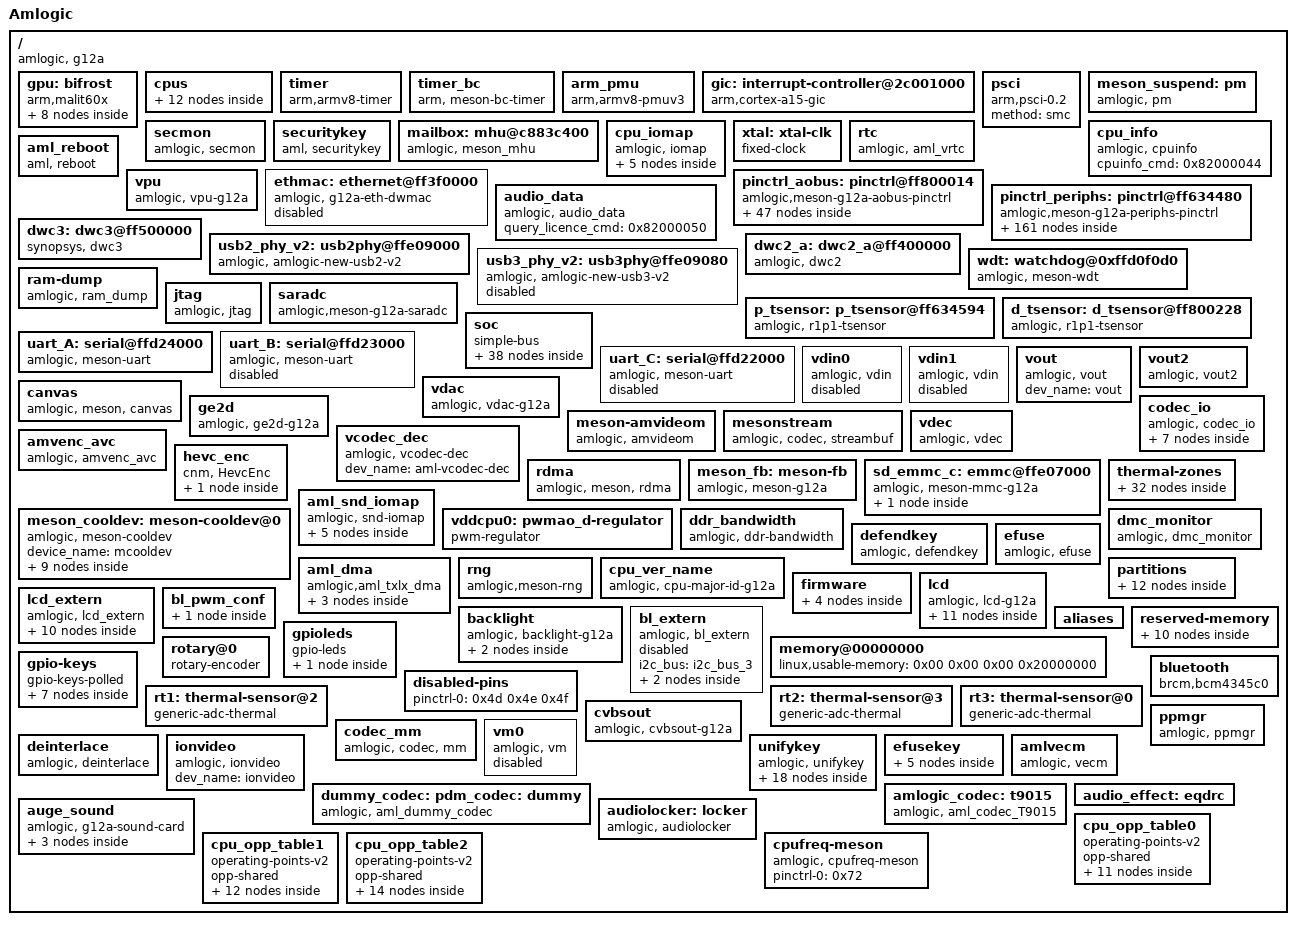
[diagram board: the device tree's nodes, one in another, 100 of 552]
/dts-v1/;

/ {
	model = "Amlogic";
	amlogic-dt-id = "g12a_evt_1g";
	compatible = "amlogic, g12a";
	interrupt-parent = <0x01>;
	#address-cells = <0x02>;
	#size-cells = <0x02>;

	gpu: bifrost {
		compatible = "arm,malit60x", "arm,malit6xx", "arm,mali-midgard";
		#cooling-cells = <0x02>;
		reg = <0x00 0xffe40000 0x00 0x4000>, <0x00 0xffd01000 0x00 0x1000>, <0x00 0xff800000 0x00 0x1000>, <0x00 0xff63c000 0x00 0x1000>, <0x00 0xffd01000 0x00 0x1000>;
		interrupt-parent = <0x01>;
		interrupts = <0x00 0xa0 0x04>, <0x00 0xa1 0x04>, <0x00 0xa2 0x04>;
		interrupt-names = "GPU", "MMU", "JOB";
		num_of_pp = <0x02>;
		sc_mpp = <0x01>;
		clocks = <0x02 0x83 0x02 0x07>;
		clock-names = "gpu_mux", "gp0_pll";
		tbl = <0x03 0x04 0x05 0x06 0x07 0x07>;

		dvfs125_cfg: clk125_cfg {
			clk_freq = <0x7735940>;
			clk_parent = "fclk_div4";
			clkp_freq = <0x1dcd6500>;
			clk_reg = <0xa03>;
			voltage = <0x47e>;
			keep_count = <0x05>;
			threshold = <0x1e 0x78>;
		};

		dvfs250_cfg: dvfs250_cfg {
			clk_freq = <0xee6b280>;
			clk_parent = "fclk_div4";
			clkp_freq = <0x1dcd6500>;
			clk_reg = <0xa01>;
			voltage = <0x47e>;
			keep_count = <0x05>;
			threshold = <0x50 0xaa>;
		};

		dvfs285_cfg: dvfs285_cfg {
			clk_freq = <0x1107a76d>;
			clk_parent = "fclk_div7";
			clkp_freq = <0x1107a76d>;
			clk_reg = <0xe00>;
			voltage = <0x47e>;
			keep_count = <0x05>;
			threshold = <0x64 0xbe>;
			phandle = <0x03>;
		};

		dvfs400_cfg: dvfs400_cfg {
			clk_freq = <0x17d78400>;
			clk_parent = "fclk_div5";
			clkp_freq = <0x17d78400>;
			clk_reg = <0xc00>;
			voltage = <0x47e>;
			keep_count = <0x05>;
			threshold = <0x98 0xcf>;
			phandle = <0x04>;
		};

		dvfs500_cfg: dvfs500_cfg {
			clk_freq = <0x1dcd6500>;
			clk_parent = "fclk_div4";
			clkp_freq = <0x1dcd6500>;
			clk_reg = <0xa00>;
			voltage = <0x47e>;
			keep_count = <0x05>;
			threshold = <0xb4 0xdc>;
			phandle = <0x05>;
		};

		dvfs666_cfg: dvfs666_cfg {
			clk_freq = <0x27bc86aa>;
			clk_parent = "fclk_div3";
			clkp_freq = <0x27bc86aa>;
			clk_reg = <0x800>;
			voltage = <0x47e>;
			keep_count = <0x05>;
			threshold = <0xd2 0xec>;
			phandle = <0x06>;
		};

		dvfs800_cfg: dvfs800_cfg {
			clk_freq = <0x2faf0800>;
			clk_parent = "fclk_div2p5";
			clkp_freq = <0x2faf0800>;
			clk_reg = <0x600>;
			voltage = <0x47e>;
			keep_count = <0x05>;
			threshold = <0xe6 0xff>;
		};

		dvfs850_cfg: dvfs850_cfg {
			clk_freq = <0x326cef80>;
			clk_parent = "gp0_pll";
			clkp_freq = <0x326cef80>;
			clk_reg = <0x200>;
			voltage = <0x47e>;
			keep_count = <0x05>;
			threshold = <0xe6 0xff>;
			phandle = <0x07>;
		};
	};

	cpus: cpus {
		#address-cells = <0x02>;
		#size-cells = <0x00>;

		cpu-map {

			cluster0: cluster0 {

				core0 {
					cpu = <0x08>;
				};

				core1 {
					cpu = <0x09>;
				};

				core2 {
					cpu = <0x0a>;
				};

				core3 {
					cpu = <0x0b>;
				};
			};
		};

		CPU0: cpu@0 {
			device_type = "cpu";
			compatible = "arm,cortex-a53", "arm,armv8";
			reg = <0x00 0x00>;
			enable-method = "psci";
			cpu-idle-states = <0x0c>;
			clocks = <0x02 0x17>, < 0x02 0x16>, < 0x02 0x00>;
			clock-names = "core_clk", "low_freq_clk_parent", "high_freq_clk_parent";
			operating-points-v2 = <0x0d>, < 0x0e>, < 0x0f>;
			cpu-supply = <0x10>;
			voltage-tolerance = <0x00>;
			clock-latency = <0xc350>;
			diff_tables_supply;
			hispeed_cpufreq_max = <0x834>;
			medspeed_cpufreq_max = <0x774>;
			lospeed_cpufreq_max = <0x708>;
			phandle = <0x08>;
		};

		CPU1: cpu@1 {
			device_type = "cpu";
			compatible = "arm,cortex-a53", "arm,armv8";
			reg = <0x00 0x01>;
			enable-method = "psci";
			cpu-idle-states = <0x0c>;
			clocks = <0x02 0x17>, < 0x02 0x16>, < 0x02 0x00>;
			clock-names = "core_clk", "low_freq_clk_parent", "high_freq_clk_parent";
			operating-points-v2 = <0x0d>, < 0x0e>, < 0x0f>;
			cpu-supply = <0x10>;
			voltage-tolerance = <0x00>;
			clock-latency = <0xc350>;
			diff_tables_supply;
			hispeed_cpufreq_max = <0x834>;
			medspeed_cpufreq_max = <0x774>;
			lospeed_cpufreq_max = <0x708>;
			phandle = <0x09>;
		};

		CPU2: cpu@2 {
			device_type = "cpu";
			compatible = "arm,cortex-a53", "arm,armv8";
			reg = <0x00 0x02>;
			enable-method = "psci";
			cpu-idle-states = <0x0c>;
			clocks = <0x02 0x17>, < 0x02 0x16>, < 0x02 0x00>;
			clock-names = "core_clk", "low_freq_clk_parent", "high_freq_clk_parent";
			operating-points-v2 = <0x0d>, < 0x0e>, < 0x0f>;
			cpu-supply = <0x10>;
			voltage-tolerance = <0x00>;
			clock-latency = <0xc350>;
			diff_tables_supply;
			hispeed_cpufreq_max = <0x834>;
			medspeed_cpufreq_max = <0x774>;
			lospeed_cpufreq_max = <0x708>;
			phandle = <0x0a>;
		};

		CPU3: cpu@3 {
			device_type = "cpu";
			compatible = "arm,cortex-a53", "arm,armv8";
			reg = <0x00 0x03>;
			enable-method = "psci";
			cpu-idle-states = <0x0c>;
			clocks = <0x02 0x17>, < 0x02 0x16>, < 0x02 0x00>;
			clock-names = "core_clk", "low_freq_clk_parent", "high_freq_clk_parent";
			operating-points-v2 = <0x0d>, < 0x0e>, < 0x0f>;
			cpu-supply = <0x10>;
			voltage-tolerance = <0x00>;
			clock-latency = <0xc350>;
			diff_tables_supply;
			hispeed_cpufreq_max = <0x834>;
			medspeed_cpufreq_max = <0x774>;
			lospeed_cpufreq_max = <0x708>;
			phandle = <0x0b>;
		};

		idle-states {
			entry-method = "arm,psci-0.2";

			CPU_SLEEP_0: cpu-sleep-0 {
				compatible = "arm,idle-state";
				arm,psci-suspend-param = <0x10000>;
				local-timer-stop;
				entry-latency-us = <0x1388>;
				exit-latency-us = <0x1388>;
				min-residency-us = <0x3a98>;
				phandle = <0x0c>;
			};
		};
	};

	timer {
		compatible = "arm,armv8-timer";
		interrupts = <0x01 0x0d 0xff08>, <0x01 0x0e 0xff08>, <0x01 0x0b 0xff08>, <0x01 0x0a 0xff08>;
	};

	timer_bc {
		compatible = "arm, meson-bc-timer";
		reg = <0x00 0xffd0f190 0x00 0x04 0x00 0xffd0f194 0x00 0x04>;
		timer_name = "Meson TimerF";
		clockevent-rating = <0x12c>;
		clockevent-shift = <0x14>;
		clockevent-features = <0x23>;
		interrupts = <0x00 0x3c 0x01>;
		bit_enable = <0x10>;
		bit_mode = <0x0c>;
		bit_resolution = <0x00>;
	};

	arm_pmu {
		compatible = "arm,armv8-pmuv3";
		interrupts = <0x00 0x89 0x04>;
		reg = <0x00 0xff634680 0x00 0x04>;
		cpumasks = <0x0f>;
		relax-timer-ns = <0x989680>;
		max-wait-cnt = <0x2710>;
	};

	gic: interrupt-controller@2c001000 {
		compatible = "arm,cortex-a15-gic", "arm,cortex-a9-gic";
		#interrupt-cells = <0x03>;
		#address-cells = <0x00>;
		interrupt-controller;
		reg = <0x00 0xffc01000 0x00 0x1000>, <0x00 0xffc02000 0x00 0x100>;
		interrupts = <0x01 0x09 0xf04>;
		phandle = <0x01>;
	};

	psci {
		compatible = "arm,psci-0.2";
		method = "smc";
	};

	meson_suspend: pm {
		compatible = "amlogic, pm";
		status = "okay";
		device_name = "aml_pm";
		reg = <0x00 0xff8000a8 0x00 0x04>, <0x00 0xff80023c 0x00 0x04>;
	};

	secmon {
		compatible = "amlogic, secmon";
		memory-region = <0x11>;
		in_base_func = <0x82000020>;
		out_base_func = <0x82000021>;
		reserve_mem_size = <0x300000>;
	};

	securitykey {
		compatible = "aml, securitykey";
		storage_query = <0x82000060>;
		storage_read = <0x82000061>;
		storage_write = <0x82000062>;
		storage_tell = <0x82000063>;
		storage_verify = <0x82000064>;
		storage_status = <0x82000065>;
		storage_list = <0x82000067>;
		storage_remove = <0x82000068>;
		storage_in_func = <0x82000023>;
		storage_out_func = <0x82000024>;
		storage_block_func = <0x82000025>;
		storage_size_func = <0x82000027>;
		storage_set_enctype = <0x8200006a>;
		storage_get_enctype = <0x8200006b>;
		storage_version = <0x8200006c>;
	};

	mailbox: mhu@c883c400 {
		compatible = "amlogic, meson_mhu";
		reg = <0x00 0xff63c400 0x00 0x4c>, <0x00 0xfffe7000 0x00 0x800>;
		interrupts = <0x00 0xd1 0x01>, <0x00 0xd2 0x01>;
		#mbox-cells = <0x01>;
		mbox-names = "cpu_to_scp_low", "cpu_to_scp_high";
		mboxes = <0x12 0x00 0x12 0x01>;
		phandle = <0x12>;
	};

	cpu_iomap {
		compatible = "amlogic, iomap";
		#address-cells = <0x02>;
		#size-cells = <0x02>;
		ranges;

		io_cbus_base {
			reg = <0x00 0xffd00000 0x00 0x26000>;
		};

		io_apb_base {
			reg = <0x00 0xffe01000 0x00 0x7f000>;
		};

		io_aobus_base {
			reg = <0x00 0xff800000 0x00 0xb000>;
		};

		io_vapb_base {
			reg = <0x00 0xff900000 0x00 0x50000>;
		};

		io_hiu_base {
			reg = <0x00 0xff63c000 0x00 0x2000>;
		};
	};

	xtal: xtal-clk {
		compatible = "fixed-clock";
		clock-frequency = <0x16e3600>;
		clock-output-names = "xtal";
		#clock-cells = <0x00>;
		phandle = <0x16>;
	};

	rtc {
		compatible = "amlogic, aml_vrtc";
		alarm_reg_addr = <0xff8000a8>;
		timer_e_addr = <0xffd0f188>;
		init_date = "2015/01/01";
		status = "okay";
	};

	cpu_info {
		compatible = "amlogic, cpuinfo";
		status = "okay";
		cpuinfo_cmd = <0x82000044>;
	};

	aml_reboot {
		compatible = "aml, reboot";
		sys_reset = <0x84000009>;
		sys_poweroff = <0x84000008>;
	};

	vpu {
		compatible = "amlogic, vpu-g12a";
		dev_name = "vpu";
		status = "okay";
		clocks = <0x02 0x95>, < 0x02 0x4c>, < 0x02 0x87>, < 0x02 0x8b>, < 0x02 0x8c>;
		clock-names = "vapb_clk", "vpu_intr_gate", "vpu_clk0", "vpu_clk1", "vpu_clk";
		clk_level = <0x07>;
	};

	ethmac: ethernet@ff3f0000 {
		compatible = "amlogic, g12a-eth-dwmac", "snps,dwmac";
		reg = <0x00 0xff3f0000 0x00 0x10000 0x00 0xff634540 0x00 0x08 0x00 0xff64c000 0x00 0xa0>;
		reg-names = "eth_base", "eth_cfg", "eth_pll";
		interrupts = <0x00 0x08 0x01>;
		interrupt-names = "macirq";
		status = "disabled";
		clocks = <0x02 0x38>;
		clock-names = "ethclk81";
		pll_val = <0x9c0040a 0x927e0000 0xac5f49e5>;
		analog_val = <0x20200000 0xc000 0x23>;
	};

	pinctrl_aobus: pinctrl@ff800014 {
		compatible = "amlogic,meson-g12a-aobus-pinctrl";
		#address-cells = <0x02>;
		#size-cells = <0x02>;
		ranges;

		gpio_ao: ao-bank@ff800014 {
			reg = <0x00 0xff800014 0x00 0x08>, <0x00 0xff800024 0x00 0x14>, <0x00 0xff80001c 0x00 0x08>;
			reg-names = "mux", "gpio", "drive-strength";
			gpio-controller;
			#gpio-cells = <0x02>;
			phandle = <0x4a>;
		};

		sd_to_ao_uart_clr_pins: sd_to_ao_uart_clr_pins {

			mux {
				groups = "GPIOAO_0", "GPIOAO_1";
				function = "gpio_aobus";
			};
		};

		sd_to_ao_uart_pins: sd_to_ao_uart_pins {

			mux {
				groups = "uart_ao_tx_a", "uart_ao_rx_a";
				function = "uart_ao_a";
				bias-pull-up;
				input-enable;
			};
		};

		ao_uart_pins: ao_uart {
			phandle = <0x1f>;

			mux {
				groups = "uart_ao_tx_a", "uart_ao_rx_a";
				function = "uart_ao_a";
			};
		};

		ao_b_uart_pins: ao_b_uart {
			phandle = <0x20>;

			mux {
				groups = "uart_ao_tx_b_2", "uart_ao_rx_b_3";
				function = "uart_ao_b";
			};
		};

		ao_i2c_master_pins1: ao_i2c_pins1 {

			mux {
				groups = "i2c_ao_sck", "i2c_ao_sda";
				function = "i2c_ao";
				drive-strength = <0x02>;
			};
		};

		ao_i2c_master_pins2: ao_i2c_pins2 {

			mux {
				groups = "i2c_ao_sck_e", "i2c_ao_sda_e";
				function = "i2c_ao";
				drive-strength = <0x02>;
			};
		};

		ao_i2c_slave_pins: ao_i2c_slave_pins {
			phandle = <0x1e>;

			mux {
				groups = "i2c_ao_slave_sck", "i2c_ao_slave_sda";
				function = "i2c_ao_slave";
			};
		};

		pwm_ao_a_pins: pwm_ao_a {

			mux {
				groups = "pwm_ao_a";
				function = "pwm_ao_a";
			};
		};

		pwm_ao_a_hiz_pins: pwm_ao_a_hiz {

			mux {
				groups = "pwm_ao_a_hiz";
				function = "pwm_ao_a";
			};
		};

		pwm_ao_b_pins: pwm_ao_b {

			mux {
				groups = "pwm_ao_b";
				function = "pwm_ao_b";
			};
		};

		pwm_ao_c_pins1: pwm_ao_c_pins1 {

			mux {
				groups = "pwm_ao_c_4";
				function = "pwm_ao_c";
			};
		};

		pwm_ao_c_pins2: pwm_ao_c_pins2 {

			mux {
				groups = "pwm_ao_c_6";
				function = "pwm_ao_c";
			};
		};

		pwm_ao_c_hiz_pins: pwm_ao_c_hiz {

			mux {
				groups = "pwm_ao_c_hiz_4";
				function = "pwm_ao_c";
			};
		};

		pwm_ao_d_pins1: pwm_ao_d_pins1 {

			mux {
				groups = "pwm_ao_d_5";
				function = "pwm_ao_d";
			};
		};

		pwm_ao_d_pins2: pwm_ao_d_pins2 {

			mux {
				groups = "pwm_ao_d_10";
				function = "pwm_ao_d";
			};
		};

		pwm_ao_d_pins3: pwm_ao_d_pins3 {
			phandle = <0x72>;

			mux {
				groups = "pwm_ao_d_e";
				function = "pwm_ao_d";
			};
		};

		aocec_a: ao_ceca {

			mux {
				groups = "cec_ao_a";
				function = "cec_ao";
			};
		};

		aocec_b: ao_cecb {

			mux {
				groups = "cec_ao_b";
				function = "cec_ao";
			};
		};

		jtag_apao_pins: jtag_apao_pin {
			phandle = <0x17>;

			mux {
				groups = "jtag_a_tdi", "jtag_a_tdo", "jtag_a_clk", "jtag_a_tms";
				function = "jtag_a";
			};
		};

		remote_pins: remote_pin {

			mux {
				groups = "remote_input_ao";
				function = "remote_input_ao";
			};
		};

		irblaster_pins: irblaster_pin {
			phandle = <0x21>;

			mux {
				groups = "remote_out_ao";
				function = "remote_out_ao";
			};
		};

		spdifout: spdifout {

			mux {
				groups = "spdif_out_ao";
				function = "spdif_out_ao";
			};
		};

		spdifout_a_mute: spdifout_a_mute {

			mux {
				groups = "GPIOAO_10";
				function = "gpio_aobus";
			};
		};
	};

	pinctrl_periphs: pinctrl@ff634480 {
		compatible = "amlogic,meson-g12a-periphs-pinctrl";
		#address-cells = <0x02>;
		#size-cells = <0x02>;
		ranges;

		gpio: banks@ff6346c0 {
			reg = <0x00 0xff6346c0 0x00 0x40>, <0x00 0xff6344e8 0x00 0x18>, <0x00 0xff634520 0x00 0x18>, <0x00 0xff634440 0x00 0x4c>, <0x00 0xff634740 0x00 0x1c>;
			reg-names = "mux", "pull", "pull-enable", "gpio", "drive-strength";
			gpio-controller;
			#gpio-cells = <0x02>;
			phandle = <0x15>;
		};

		emmc_clk_cmd_pins: emmc_clk_cmd_pins {
			phandle = <0x2b>;

			mux {
				groups = "emmc_clk", "emmc_cmd";
				function = "emmc";
				input-enable;
				bias-pull-up;
			};
		};

		emmc_conf_pull_up: emmc_conf_pull_up {
			phandle = <0x2c>;

			mux {
				groups = "emmc_nand_d7", "emmc_nand_d6", "emmc_nand_d5", "emmc_nand_d4", "emmc_nand_d3", "emmc_nand_d2", "emmc_nand_d1", "emmc_nand_d0", "emmc_clk", "emmc_cmd";
				function = "emmc";
				input-enable;
				bias-pull-up;
			};
		};

		emmc_conf_pull_done: emmc_conf_pull_done {
			phandle = <0x2d>;

			mux {
				groups = "emmc_nand_ds";
				function = "emmc";
				input-enable;
				bias-pull-down;
			};
		};

		sd_clk_cmd_pins: sd_clk_cmd_pins {

			mux {
				groups = "sdcard_cmd_c";
				function = "sdcard";
				input-enable;
				bias-pull-up;
				drive-strength = <0x03>;
			};

			mux1 {
				groups = "sdcard_clk_c";
				function = "sdcard";
				bias-pull-up;
				output-high;
				drive-strength = <0x03>;
			};
		};

		sd_all_pins: sd_all_pins {

			mux {
				groups = "sdcard_d0_c", "sdcard_d1_c", "sdcard_d2_c", "sdcard_d3_c", "sdcard_cmd_c";
				function = "sdcard";
				input-enable;
				bias-pull-up;
				drive-strength = <0x03>;
			};

			mux1 {
				groups = "sdcard_clk_c";
				function = "sdcard";
				bias-pull-up;
				output-high;
				drive-strength = <0x03>;
			};
		};

		sd_1bit_pins: sd_1bit_pins {

			mux {
				groups = "sdcard_d0_c", "sdcard_cmd_c";
				function = "sdcard";
				input-enable;
				bias-pull-up;
				drive-strength = <0x03>;
			};

			mux1 {
				groups = "sdcard_clk_c";
				function = "sdcard";
				bias-pull-up;
				output-high;
				drive-strength = <0x03>;
			};
		};

		sd_clr_all_pins: sd_clr_all_pins {

			mux {
				groups = "GPIOC_0", "GPIOC_1", "GPIOC_2", "GPIOC_3", "GPIOC_5";
				function = "gpio_periphs";
				output-high;
			};

			mux1 {
				groups = "GPIOC_4";
				function = "gpio_periphs";
				output-low;
			};
		};

		sd_clr_noall_pins: sd_clr_noall_pins {

			mux {
				groups = "GPIOC_0", "GPIOC_1", "GPIOC_4", "GPIOC_5";
				function = "gpio_periphs";
				output-high;
			};
		};

		ao_to_sd_uart_pins: ao_to_sd_uart_pins {

			mux {
				groups = "uart_ao_tx_a_c3", "uart_ao_rx_a_c2";
				function = "uart_ao_a_ee";
				bias-pull-up;
				input-enable;
			};
		};

		sdio_clk_cmd_pins: sdio_clk_cmd_pins {

			mux {
				groups = "sdio_clk", "sdio_cmd";
				function = "sdio";
				input-enable;
				bias-pull-up;
				drive-strength = <0x03>;
			};
		};

		sdio_all_pins: sdio_all_pins {

			mux {
				groups = "sdio_d0", "sdio_d1", "sdio_d2", "sdio_d3", "sdio_clk", "sdio_cmd";
				function = "sdio";
				input-enable;
				bias-pull-up;
				drive-strength = <0x03>;
			};
		};

		sdio_x_clk_cmd_pins: sdio_x_clk_cmd_pins {

			mux {
				groups = "GPIOX_5";
				function = "gpio_periphs";
				input-enable;
				bias-pull-up;
				drive-strength = <0x03>;
			};

			mux1 {
				groups = "GPIOX_4";
				function = "gpio_periphs";
				bias-pull-up;
				output-high;
				drive-strength = <0x03>;
			};
		};

		sdio_x_all_pins: sdio_x_all_pins {

			mux {
				groups = "GPIOX_0", "GPIOX_1", "GPIOX_2", "GPIOX_3", "GPIOX_5";
				function = "gpio_periphs";
				input-enable;
				bias-pull-up;
				drive-strength = <0x03>;
			};

			mux1 {
				groups = "GPIOX_4";
				function = "gpio_periphs";
				bias-pull-up;
				output-high;
				drive-strength = <0x03>;
			};
		};

		sdio_x_en_pins: sdio_x_en_pins {

			mux {
				groups = "sdio_dummy";
				function = "sdio";
				bias-pull-up;
				output-high;
			};
		};

		sdio_x_clr_pins: sdio_x_clr_pins {

			mux {
				groups = "GPIOV_0";
				function = "gpio_periphs";
				bias-pull-up;
				output-low;
			};

			mux1 {
				groups = "GPIOX_4";
				function = "gpio_periphs";
				output-low;
			};
		};

		all_nand_pins: all_nand_pins {

			mux {
				groups = "emmc_nand_d0", "emmc_nand_d1", "emmc_nand_d2", "emmc_nand_d3", "emmc_nand_d4", "emmc_nand_d5", "emmc_nand_d6", "emmc_nand_d7", "nand_ce0", "nand_ale", "nand_cle", "nand_wen_clk", "nand_ren_wr", "nand_rb0";
				function = "nand";
				input-enable;
			};
		};

		nand_cs_pins: nand_cs {

			mux {
				groups = "nand_ce0";
				function = "nand";
			};
		};

		i2c0_master_pins1: i2c0_pins1 {

			mux {
				groups = "i2c0_sda_c", "i2c0_sck_c";
				function = "i2c0";
				drive-strength = <0x02>;
			};
		};

		i2c0_master_pins2: i2c0_pins2 {

			mux {
				groups = "i2c0_sda_z0", "i2c0_sck_z1";
				function = "i2c0";
				drive-strength = <0x02>;
			};
		};

		i2c0_master_pins3: i2c0_pins3 {

			mux {
				groups = "i2c0_sda_z7", "i2c0_sck_z8";
				function = "i2c0";
				drive-strength = <0x02>;
			};
		};

		i2c1_master_pins1: i2c1_pins1 {

			mux {
				groups = "i2c1_sda_x", "i2c1_sck_x";
				function = "i2c1";
				drive-strength = <0x02>;
			};
		};

		i2c1_master_pins2: i2c1_pins2 {

			mux {
				groups = "i2c1_sda_h2", "i2c1_sck_h3";
				function = "i2c1";
				drive-strength = <0x02>;
			};
		};

		i2c1_master_pins3: i2c1_pins3 {

			mux {
				groups = "i2c1_sda_h6", "i2c1_sck_h7";
				function = "i2c1";
				drive-strength = <0x02>;
			};
		};

		i2c2_master_pins1: i2c2_pins1 {

			mux {
				groups = "i2c2_sda_x", "i2c2_sck_x";
				function = "i2c2";
				drive-strength = <0x02>;
			};
		};

		i2c2_master_pins2: i2c2_pins2 {
			phandle = <0x1a>;

			mux {
				groups = "i2c2_sda_z", "i2c2_sck_z";
				function = "i2c2";
				drive-strength = <0x02>;
			};
		};

		i2c3_master_pins1: i2c3_pins1 {

			mux {
				groups = "i2c3_sda_h", "i2c3_sck_h";
				function = "i2c3";
				drive-strength = <0x02>;
			};
		};

		i2c3_master_pins2: i2c3_pins2 {

			mux {
				groups = "i2c3_sda_a", "i2c3_sck_a";
				function = "i2c3";
				drive-strength = <0x02>;
			};
		};

		pwm_a_pins: pwm_a {

			mux {
				groups = "pwm_a";
				function = "pwm_a";
			};
		};

		pwm_b_pins1: pwm_b_pins1 {

			mux {
				groups = "pwm_b_x7";
				function = "pwm_b";
			};
		};

		pwm_b_pins2: pwm_b_pins2 {

			mux {
				groups = "pwm_b_x19";
				function = "pwm_b";
			};
		};

		pwm_c_pins1: pwm_c_pins1 {

			mux {
				groups = "pwm_c_c4";
				function = "pwm_c";
			};
		};

		pwm_c_pins2: pwm_c_pins2 {

			mux {
				groups = "pwm_c_x5";
				function = "pwm_c";
			};
		};

		pwm_c_pins3: pwm_c_pins3 {

			mux {
				groups = "pwm_c_x8";
				function = "pwm_c";
			};
		};

		pwm_d_pins1: pwm_d_pins1 {

			mux {
				groups = "pwm_d_x3";
				function = "pwm_d";
			};
		};

		pwm_d_pins2: pwm_d_pins2 {

			mux {
				groups = "pwm_d_x6";
				function = "pwm_d";
			};
		};

		pwm_e_pins: pwm_e {

			mux {
				groups = "pwm_e";
				function = "pwm_e";
			};
		};

		pwm_f_pins1: pwm_f_pins1 {

			mux {
				groups = "pwm_f_x";
				function = "pwm_f";
			};
		};

		pwm_f_pins2: pwm_f_pins2 {
			phandle = <0x46>;

			mux {
				groups = "pwm_f_h";
				function = "pwm_f";
			};
		};

		spicc0_pins_x: spicc0_pins_x {

			mux {
				groups = "spi0_mosi_x", "spi0_miso_x", "spi0_clk_x";
				function = "spi0";
				drive-strength = <0x01>;
			};
		};

		spicc0_pins_c: spicc0_pins_c {

			mux {
				groups = "spi0_mosi_c", "spi0_miso_c", "spi0_ss0_c", "spi0_clk_c";
				function = "spi0";
				drive-strength = <0x01>;
			};
		};

		spicc1_pins: spicc1_pins {

			mux {
				groups = "spi1_mosi", "spi1_miso", "spi1_clk";
				function = "spi1";
				drive-strength = <0x01>;
			};
		};

		a_uart_pins: a_uart {
			phandle = <0x27>;

			mux {
				groups = "uart_tx_a", "uart_rx_a", "uart_cts_a", "uart_rts_a";
				function = "uart_a";
			};
		};

		b_uart_pins: b_uart {
			phandle = <0x28>;

			mux {
				groups = "uart_tx_b", "uart_rx_b";
				function = "uart_b";
			};
		};

		c_uart_pins: c_uart {
			phandle = <0x29>;

			mux {
				groups = "uart_tx_c", "uart_rx_c";
				function = "uart_c";
			};
		};

		hdmitx_hpd: hdmitx_hpd {

			mux {
				groups = "hdmitx_hpd_in";
				function = "hdmitx";
				bias-disable;
			};
		};

		hdmitx_hpd_gpio: hdmitx_hpd_gpio {

			mux {
				groups = "GPIOH_1";
				function = "gpio_periphs";
				bias-disable;
			};
		};

		hdmitx_ddc: hdmitx_ddc {

			mux {
				groups = "hdmitx_sda", "hdmitx_sck";
				function = "hdmitx";
				bias-disable;
				drive-strength = <0x03>;
			};
		};

		eecec_a: ee_ceca {

			mux {
				groups = "cec_ao_a_ee";
				function = "cec_ao_ee";
			};
		};

		eecec_b: ee_cecb {

			mux {
				groups = "cec_ao_b_ee";
				function = "cec_ao_ee";
			};
		};

		internal_eth_pins: internal_eth_pins {

			mux {
				groups = "eth_link_led", "eth_act_led";
				function = "eth";
			};
		};

		internal_gpio_pins: internal_gpio_pins {

			mux {
				groups = "GPIOZ_14", "GPIOZ_15";
				function = "gpio_periphs";
				bias-disable;
				input-enable;
			};
		};

		external_eth_pins: external_eth_pins {

			mux {
				groups = "eth_mdio", "eth_mdc", "eth_rgmii_rx_clk", "eth_rx_dv", "eth_rxd0", "eth_rxd1", "eth_rxd2_rgmii", "eth_rxd3_rgmii", "eth_rgmii_tx_clk", "eth_txen", "eth_txd0", "eth_txd1", "eth_txd2_rgmii", "eth_txd3_rgmii";
				function = "eth";
				drive-strength = <0x03>;
			};
		};

		jtag_apee_pins: jtag_apee_pin {
			phandle = <0x18>;

			mux {
				groups = "jtag_b_tdi", "jtag_b_tdo", "jtag_b_clk", "jtag_b_tms";
				function = "jtag_b";
			};
		};

		tdmout_a: tdmout_a {
			phandle = <0x24>;

			mux {
				groups = "tdma_sclk", "tdma_fs", "tdma_dout0";
				function = "tdma_out";
			};
		};

		tdmin_a: tdmin_a {
			phandle = <0x25>;

			mux {
				groups = "tdma_din1";
				function = "tdma_in";
			};
		};

		spdifin: spdifin {
			status = "disabled";
		};

		spotify_buttons: spotify_buttons {
			phandle = <0x4b>;

			mux {
				pins = "GPIOA_0", "GPIOA_1", "GPIOA_2", "GPIOA_3", "GPIOAO_3", "GPIOA_5";
				bias-disable;
				input-enable;
			};
		};

		spotify_rotary: spotify_rotary {
			phandle = <0x4c>;

			mux {
				pins = "GPIOZ_7", "GPIOZ_8", "GPIOZ_9";
				bias-disable;
				input-enable;
			};
		};

		spotify_touch_i2c: spotify_touch_i2c {
			phandle = <0x19>;

			mux {
				groups = "i2c0_sda_z0", "i2c0_sck_z1";
				function = "i2c0";
				drive-strength = "1";
			};
		};

		spotify_touch_gpio: spotify_touch_gpio {

			mux {
				groups = "GPIOZ_3", "GPIOZ_4";
				function = "gpio_periphs";
				drive-strength = "1";
			};
		};

		spotify_prox_gpio: spotify_prox_gpio {
			phandle = <0x1b>;

			mux {
				pins = "GPIOZ_10";
				bias-pull-down;
			};
		};

		spotify_imu_gpio: spotify_imu_gpio {
			phandle = <0x1c>;

			mux {
				pins = "GPIOZ_12", "GPIOZ_13";
				bias-pull-down;
			};
		};

		spotify_lcd_reset_pin: spotify_lcd_reset_pin {

			mux {
				pins = "GPIOZ_5";
				function = "gpio_periphs";
				bias-disable;
				drive-strength = "1";
			};
		};

		spotify_mfi_i2c_pins: spotify_mfi_i2c_pins {
			phandle = <0x1d>;

			mux {
				groups = "i2c3_sda_a", "i2c3_sck_a";
				function = "i2c3";
				bias-disable;
				drive-strength = <0x02>;
			};
		};

		spotify_bluetooth_bt_wake_host: spotify_bluetooth_bt_wake_host {
			pins = "GPIOX_6";
			bias-disable;
			input-enable;
		};

		spotify_bluetooth_host_wake_bt: spotify_bluetooth_host_wake_bt {
			pins = "GPIOX_7";
			bias-disable;
			output-enable;
			drive-strength = "1";
		};

		spotify_disabled_pins_c: spotify_disabled_pins_c {
			phandle = <0x4e>;

			mux {
				pins = "GPIOC_0", "GPIOC_1", "GPIOC_2", "GPIOC_3", "GPIOC_5", "GPIOC_6", "GPIOC_7";
				bias-pull-down;
				output-low;
			};
		};

		spotify_disabled_pins_a: spotify_disabled_pins_a {
			phandle = <0x4d>;

			mux {
				pins = "GPIOA_10", "GPIOA_11", "GPIOA_12", "GPIOA_13";
				bias-pull-down;
				output-low;
			};
		};

		spotify_disabled_pins_h: spotify_disabled_pins_h {
			phandle = <0x4f>;

			mux {
				pins = "GPIOH_0", "GPIOH_1", "GPIOH_2", "GPIOH_3", "GPIOH_6", "GPIOH_7", "GPIOH_8";
				bias-pull-down;
				output-low;
			};
		};

		tp_int_input: eint@0 {

			mux {
				pins = "GPIOZ_4";
				bias-pull-up;
			};
		};

		state_rst_output0: rstoutput0 {

			mux {
				pins = "GPIOZ_3";
				output-low;
				bias-pull-down;
				drive-strength = "1";
			};
		};

		state_rst_output1: rstoutput1 {

			mux {
				pins = "GPIOZ_3";
				output-high;
				bias-pull-up;
				drive-strength = "1";
			};
		};

		pdmin: pdmin {
			phandle = <0x26>;

			mux {
				groups = "pdm_din0_a", "pdm_din1_a", "pdm_dclk_a";
				function = "pdm";
				drive-strength = <0x01>;
			};
		};

		bl_enable: bl_enable {

			mux {
				pins = "GPIOH_4";
				function = "gpio_periphs";
				bias-pull-up;
				output-high;
			};
		};

		bl_pwm_off_pins: bl_pwm_off_pin {
			phandle = <0x47>;

			mux {
				pins = "GPIOH_5";
				function = "gpio_periphs";
				output-low;
				drive-strength = "1";
			};
		};

		clk12_24_z_pins: clk12_24_z_pins {

			mux {
				groups = "clk12_24_z";
				function = "clk12_24_ee";
				drive-strength = <0x03>;
			};
		};

		gen_clk_ee_z: gen_clk_ee_z {

			mux {
				groups = "gen_clk_ee_z";
				function = "gen_clk_ee";
				drive-strength = <0x03>;
			};
		};

		cam_dvp_pins: cam_dvp_pins {

			mux {
				groups = "bt656_a_vs", "bt656_a_hs", "bt656_a_clk", "bt656_a_din0", "bt656_a_din1", "bt656_a_din2", "bt656_a_din3", "bt656_a_din4", "bt656_a_din5", "bt656_a_din6", "bt656_a_din7";
				function = "bt656";
			};
		};
	};

	audio_data: audio_data {
		compatible = "amlogic, audio_data";
		query_licence_cmd = <0x82000050>;
		status = "okay";
	};

	dwc3: dwc3@ff500000 {
		compatible = "synopsys, dwc3";
		status = "okay";
		reg = <0x00 0xff500000 0x00 0x100000>;
		interrupts = <0x00 0x1e 0x04>;
		usb-phy = <0x13>, < 0x14>;
		cpu-type = "gxl";
		clock-src = "usb3.0";
		clocks = <0x02 0x41>;
		clock-names = "dwc_general";
	};

	usb2_phy_v2: usb2phy@ffe09000 {
		compatible = "amlogic, amlogic-new-usb2-v2";
		status = "okay";
		reg = <0x00 0xffe09000 0x00 0x80 0x00 0xffd01008 0x00 0x100 0x00 0xff636000 0x00 0x2000 0x00 0xff63a000 0x00 0x2000>;
		pll-setting-1 = <0x9400414>;
		pll-setting-2 = <0x927e0000>;
		pll-setting-3 = <0xac5f49e5>;
		pll-setting-4 = <0xfe18>;
		pll-setting-5 = <0x8000fff>;
		pll-setting-6 = <0x78000>;
		pll-setting-7 = <0xe0004>;
		pll-setting-8 = <0xe000c>;
		portnum = <0x02>;
		phandle = <0x13>;
	};

	usb3_phy_v2: usb3phy@ffe09080 {
		compatible = "amlogic, amlogic-new-usb3-v2";
		status = "disabled";
		reg = <0x00 0xffe09080 0x00 0x20>;
		phy-reg = <0xff646000>;
		phy-reg-size = <0x2000>;
		usb2-phy-reg = <0xffe09000>;
		usb2-phy-reg-size = <0x80>;
		interrupts = <0x00 0x10 0x04>;
		clocks = <0x02 0x18>;
		clock-names = "pcie_refpll";
		portnum = <0x01>;
		otg = <0x01>;
		gpio-vbus-power = "GPIOH_6";
		gpios = <0x15 0x16 0x00>;
		phandle = <0x14>;
	};

	dwc2_a: dwc2_a@ff400000 {
		compatible = "amlogic, dwc2";
		status = "okay";
		device_name = "dwc2_a";
		reg = <0x00 0xff400000 0x00 0x40000>;
		interrupts = <0x00 0x1f 0x04>;
		pl-periph-id = <0x00>;
		clock-src = "usb0";
		port-id = <0x00>;
		port-type = <0x02>;
		port-speed = <0x00>;
		port-config = <0x00>;
		port-dma = <0x00>;
		port-id-mode = <0x00>;
		usb-fifo = <0x2d8>;
		cpu-type = "v2";
		phy-reg = <0xffe09000>;
		phy-reg-size = <0xa0>;
		phy-interface = <0x00>;
		clocks = <0x02 0x41 0x02 0x49>;
		clock-names = "usb_general", "usb1";
		controller-type = <0x03>;
	};

	wdt: watchdog@0xffd0f0d0 {
		compatible = "amlogic, meson-wdt";
		status = "okay";
		default_timeout = <0x0a>;
		reset_watchdog_method = <0x01>;
		reset_watchdog_time = <0x02>;
		shutdown_timeout = <0x0a>;
		firmware_timeout = <0x06>;
		suspend_timeout = <0x06>;
		reg = <0x00 0xffd0f0d0 0x00 0x10>;
		clock-names = "xtal";
		clocks = <0x16>;
	};

	ram-dump {
		compatible = "amlogic, ram_dump";
		status = "okay";
		reg = <0x00 0xff6345e0 0x00 0x04>;
		reg-names = "PREG_STICKY_REG8";
		store_device = "data";
	};

	jtag {
		compatible = "amlogic, jtag";
		status = "okay";
		select = "disable";
		pinctrl-names = "jtag_apao_pins", "jtag_apee_pins";
		pinctrl-0 = <0x17>;
		pinctrl-1 = <0x18>;
	};

	saradc: saradc {
		compatible = "amlogic,meson-g12a-saradc";
		status = "okay";
		#io-channel-cells = <0x01>;
		clocks = <0x16>, < 0x02 0x103>;
		clock-names = "xtal", "saradc_clk";
		interrupts = <0x00 0xc8 0x01>;
		reg = <0x00 0xff809000 0x00 0x48>;
		phandle = <0x50>;
	};

	p_tsensor: p_tsensor@ff634594 {
		compatible = "amlogic, r1p1-tsensor";
		device_name = "meson-pthermal";
		status = "okay";
		reg = <0x00 0xff634800 0x00 0x50>, <0x00 0xff800268 0x00 0x04>;
		cal_type = <0x01>;
		cal_a = <0x144>;
		cal_b = <0x1a8>;
		cal_c = <0xc57>;
		cal_d = <0x24c3>;
		rtemp = <0x1c138>;
		interrupts = <0x00 0x23 0x00>;
		clocks = <0x02 0xd6>;
		clock-names = "ts_comp";
		#thermal-sensor-cells = <0x01>;
		phandle = <0x2e>;
	};

	d_tsensor: d_tsensor@ff800228 {
		compatible = "amlogic, r1p1-tsensor";
		device_name = "meson-dthermal";
		status = "okay";
		reg = <0x00 0xff634c00 0x00 0x50>, <0x00 0xff800230 0x00 0x04>;
		cal_type = <0x01>;
		cal_a = <0x144>;
		cal_b = <0x1a8>;
		cal_c = <0xc57>;
		cal_d = <0x24c3>;
		rtemp = <0x1c138>;
		interrupts = <0x00 0x24 0x00>;
		clocks = <0x02 0xd6>;
		clock-names = "ts_comp";
		#thermal-sensor-cells = <0x01>;
		phandle = <0x34>;
	};

	soc {
		compatible = "simple-bus";
		#address-cells = <0x02>;
		#size-cells = <0x02>;
		ranges;

		cbus: cbus@ffd00000 {
			compatible = "simple-bus";
			reg = <0x00 0xffd00000 0x00 0x26000>;
			#address-cells = <0x02>;
			#size-cells = <0x02>;
			ranges = <0x00 0x00 0x00 0xffd00000 0x00 0x26000>;

			gpio_intc: interrupt-controller@f080 {
				compatible = "amlogic,meson-gpio-intc-ext", "amlogic,meson-g12a-gpio-intc";
				reg = <0x00 0xf080 0x00 0x10>;
				interrupt-controller;
				#interrupt-cells = <0x02>;
				amlogic,channel-interrupts = <0x40 0x41 0x42 0x43 0x44 0x45 0x46 0x47>;
				status = "okay";
			};

			meson_clk_msr {
				compatible = "amlogic, gxl_measure";
				reg = <0x00 0x18004 0x00 0x04 0x00 0x1800c 0x00 0x04>;
				ringctrl = <0xff6345fc>;
			};

			pwm_ab: pwm@1b000 {
				compatible = "amlogic,g12a-ee-pwm";
				reg = <0x00 0x1b000 0x00 0x20>;
				#pwm-cells = <0x03>;
				clocks = <0x16>, < 0x16>, < 0x16>, < 0x16>;
				clock-names = "clkin0", "clkin1", "clkin2", "clkin3";
				status = "disabled";
			};

			pwm_cd: pwm@1a000 {
				compatible = "amlogic,g12a-ee-pwm";
				reg = <0x00 0x1a000 0x00 0x20>;
				#pwm-cells = <0x03>;
				clocks = <0x16>, < 0x16>, < 0x16>, < 0x16>;
				clock-names = "clkin0", "clkin1", "clkin2", "clkin3";
				status = "disabled";
			};

			pwm_ef: pwm@19000 {
				compatible = "amlogic,g12a-ee-pwm";
				reg = <0x00 0x19000 0x00 0x20>;
				#pwm-cells = <0x03>;
				clocks = <0x16>, < 0x16>, < 0x16>, < 0x16>;
				clock-names = "clkin0", "clkin1", "clkin2", "clkin3";
				status = "okay";
				phandle = <0x49>;
			};

			i2c0: i2c@1f000 {
				compatible = "amlogic,meson-g12a-i2c";
				status = "okay";
				reg = <0x00 0x1f000 0x00 0x20>;
				interrupts = <0x00 0x15 0x01>, <0x00 0x5b 0x01>;
				#address-cells = <0x01>;
				#size-cells = <0x00>;
				clocks = <0x02 0x2a>;
				clock-names = "clk_i2c";
				pinctrl-names = "default";
				pinctrl-0 = <0x19>;
				clock-frequency = <0x61a80>;

				tlsc6x_ts@2e {
					compatible = "tlsc6x,tlsc6x_ts";
					status = "okay";
					reg = <0x2e>;
					reset-gpio = <0x15 0x03 0x00>;
					irq-gpio = <0x15 0x04 0x00>;
					polling-mode = <0x00>;
					TP_MAX_X = <0x1e0>;
					TP_MAX_Y = <0x320>;
				};
			};

			i2c1: i2c@1e000 {
				compatible = "amlogic,meson-g12a-i2c";
				status = "disabled";
				reg = <0x00 0x1e000 0x00 0x20>;
				interrupts = <0x00 0xd6 0x01>, <0x00 0x5c 0x01>;
				#address-cells = <0x01>;
				#size-cells = <0x00>;
				clocks = <0x02 0x2a>;
				clock-names = "clk_i2c";
			};

			i2c2: i2c@1d000 {
				compatible = "amlogic,meson-g12a-i2c";
				status = "okay";
				reg = <0x00 0x1d000 0x00 0x20>;
				interrupts = <0x00 0xd7 0x01>, <0x00 0x5e 0x01>;
				#address-cells = <0x01>;
				#size-cells = <0x00>;
				clocks = <0x02 0x2a>;
				clock-names = "clk_i2c";
				pinctrl-names = "default";
				pinctrl-0 = <0x1a 0x1b 0x1c>;
				clock-frequency = <0x61a80>;

				lis2dh12@18 {
					compatible = "st,lis2dh12-accel";
					reg = <0x18>;
				};

				max20332@35 {
					reg = <0x35>;
				};

				tmd27721@39 {
					compatible = "amstaos,tmd2772";
					reg = <0x39>;
					enable-proxy = "false";
					enable-als = "true";
				};
			};

			i2c3: i2c@1c000 {
				compatible = "amlogic,meson-g12a-i2c";
				status = "okay";
				reg = <0x00 0x1c000 0x00 0x20>;
				interrupts = <0x00 0x27 0x01>, <0x00 0x5f 0x01>;
				#address-cells = <0x01>;
				#size-cells = <0x00>;
				clocks = <0x02 0x2a>;
				clock-names = "clk_i2c";
				pinctrl-names = "default";
				pinctrl-0 = <0x1d>;
				clock-frequency = <0x61a80>;

				mfi@10 {
					compatible = "apple_mfi_auth";
					reg = <0x10>;
				};
			};

			spicc0: spi@13000 {
				compatible = "amlogic,meson-g12a-spicc";
				reg = <0x00 0x13000 0x00 0x44>;
				interrupts = <0x00 0x51 0x04>;
				clocks = <0x02 0x29>, < 0x02 0xd1>;
				clock-names = "core", "comp";
				#address-cells = <0x01>;
				#size-cells = <0x00>;
				status = "disabled";
			};

			spicc1: spi@15000 {
				compatible = "amlogic,meson-g12a-spicc";
				reg = <0x00 0x15000 0x00 0x44>;
				interrupts = <0x00 0x5a 0x04>;
				clocks = <0x02 0x2f>, < 0x02 0xd5>;
				clock-names = "core", "comp";
				#address-cells = <0x01>;
				#size-cells = <0x00>;
				status = "disabled";
			};
		};

		aobus: aobus@ff800000 {
			compatible = "simple-bus";
			reg = <0x00 0xff800000 0x00 0xb000>;
			#address-cells = <0x02>;
			#size-cells = <0x02>;
			ranges = <0x00 0x00 0x00 0xff800000 0x00 0xb000>;

			cpu_version {
				reg = <0x00 0x220 0x00 0x04>;
			};

			aoclkc: clock-controller@0 {
				compatible = "amlogic,g12a-aoclkc";
				#clock-cells = <0x01>;
				reg = <0x00 0x00 0x00 0x320>;
			};

			pwm_AO_ab: pwm@7000 {
				compatible = "amlogic,g12a-ao-pwm";
				reg = <0x00 0x7000 0x00 0x20>;
				#pwm-cells = <0x03>;
				clocks = <0x16>, < 0x16>, < 0x16>, < 0x16>;
				clock-names = "clkin0", "clkin1", "clkin2", "clkin3";
				status = "disabled";
			};

			pwm_AO_cd: pwm@2000 {
				compatible = "amlogic,g12a-ao-pwm";
				reg = <0x00 0x2000 0x00 0x20>;
				#pwm-cells = <0x03>;
				clocks = <0x16>, < 0x16>, < 0x16>, < 0x16>;
				clock-names = "clkin0", "clkin1", "clkin2", "clkin3";
				status = "okay";
				phandle = <0x38>;
			};

			i2c_AO: i2c@5000 {
				compatible = "amlogic,meson-g12a-i2c";
				status = "disabled";
				reg = <0x00 0x5000 0x00 0x20>;
				interrupts = <0x00 0xc3 0x01>, <0x00 0xc9 0x01>;
				#address-cells = <0x01>;
				#size-cells = <0x00>;
				clocks = <0x02 0x2a>;
				clock-names = "clk_i2c";
			};

			i2c_AO_slave: i2c_slave@6000 {
				compatible = "amlogic, meson-i2c-slave";
				status = "disabled";
				reg = <0x00 0x6000 0x00 0x20>;
				interrupts = <0x00 0xc2 0x01>;
				pinctrl-names = "default";
				pinctrl-0 = <0x1e>;
			};

			uart_AO: serial@3000 {
				compatible = "amlogic, meson-uart";
				reg = <0x00 0x3000 0x00 0x18>;
				interrupts = <0x00 0xc1 0x01>;
				status = "okay";
				clocks = <0x16>;
				clock-names = "clk_uart";
				xtal_tick_en = <0x02>;
				fifosize = <0x40>;
				pinctrl-names = "default";
				support-sysrq = <0x00>;
				pinctrl-0 = <0x1f>;
			};

			uart_AO_B: serial@4000 {
				compatible = "amlogic, meson-uart";
				reg = <0x00 0x4000 0x00 0x18>;
				interrupts = <0x00 0xc5 0x01>;
				status = "disabled";
				clocks = <0x16>;
				clock-names = "clk_uart";
				fifosize = <0x40>;
				pinctrl-names = "default";
				pinctrl-0 = <0x20>;
			};

			irblaster: meson-irblaster@14c {
				compatible = "amlogic, meson_irblaster";
				reg = <0x00 0x14c 0x00 0x10>, <0x00 0x40 0x00 0x04>;
				#irblaster-cells = <0x02>;
				pinctrl-names = "default";
				pinctrl-0 = <0x21>;
				interrupts = <0x00 0xc6 0x01>;
				status = "disabled";
			};
		};

		periphs: periphs@ff634400 {
			compatible = "simple-bus";
			reg = <0x00 0xff634400 0x00 0x400>;
			#address-cells = <0x02>;
			#size-cells = <0x02>;
			ranges = <0x00 0x00 0x00 0xff634400 0x00 0x400>;
		};

		hiubus: hiubus@ff63c000 {
			compatible = "simple-bus";
			reg = <0x00 0xff63c000 0x00 0x2000>;
			#address-cells = <0x02>;
			#size-cells = <0x02>;
			ranges = <0x00 0x00 0x00 0xff63c000 0x00 0x2000>;

			clkc: clock-controller@0 {
				compatible = "amlogic,g12a-clkc";
				#clock-cells = <0x01>;
				reg = <0x00 0x00 0x00 0x320>;
				phandle = <0x02>;
			};
		};

		ion_dev {
			compatible = "amlogic, ion_dev";
			memory-region = <0x22>;
		};

		audiobus: audiobus@0xff642000 {
			compatible = "amlogic, audio-controller", "simple-bus";
			reg = <0x00 0xff642000 0x00 0x2000>;
			#address-cells = <0x02>;
			#size-cells = <0x02>;
			ranges = <0x00 0x00 0x00 0xff642000 0x00 0x2000>;

			clkaudio: audio_clocks {
				compatible = "amlogic, g12a-audio-clocks";
				#clock-cells = <0x01>;
				reg = <0x00 0x00 0x00 0xb0>;
				phandle = <0x23>;
			};

			ddr_manager {
				compatible = "amlogic, g12a-audio-ddr-manager";
				interrupts = <0x00 0x94 0x01 0x00 0x95 0x01 0x00 0x96 0x01 0x00 0x98 0x01 0x00 0x99 0x01 0x00 0x9a 0x01>;
				interrupt-names = "toddr_a", "toddr_b", "toddr_c", "frddr_a", "frddr_b", "frddr_c";
			};

			aml_tdma: tdma {
				compatible = "amlogic, g12a-snd-tdma";
				#sound-dai-cells = <0x00>;
				dai-tdm-lane-slot-mask-in = <0x00 0x01>;
				dai-tdm-oe-lane-slot-mask-out = <0x01 0x00>;
				dai-tdm-clk-sel = <0x00>;
				clocks = <0x23 0x17 0x02 0x0c>;
				clock-names = "mclk", "clk_srcpll";
				pinctrl-names = "tdm_pins";
				pinctrl-0 = <0x24 0x25>;
			};

			aml_pdm: pdm {
				compatible = "amlogic, g12a-snd-pdm";
				#sound-dai-cells = <0x00>;
				clocks = <0x23 0x01 0x02 0x03 0x02 0x0f 0x23 0x1f 0x23 0x20>;
				clock-names = "gate", "sysclk_srcpll", "dclk_srcpll", "pdm_dclk", "pdm_sysclk";
				pinctrl-names = "pdm_pins";
				pinctrl-0 = <0x26>;
				filter_mode = <0x01>;
				status = "okay";
				phandle = <0x70>;
			};

			aml_loopback: loopback {
				compatible = "amlogic, snd-loopback";
				clocks = <0x02 0x0d>;
				clock-names = "datalb_mpll";
				lb_mode = <0x00>;
				datain_src = <0x04>;
				datain_chnum = <0x08>;
				datain_chmask = <0x3f>;
				datalb_src = <0x00>;
				datalb_chnum = <0x02>;
				datalb-lane-mask-in = <0x00 0x01>;
				datalb_chmask = <0x03>;
				status = "okay";
				phandle = <0x6d>;
			};

			audioresample: resample {
				compatible = "amlogic, g12a-resample";
				clocks = <0x02 0x0f 0x23 0x1c 0x23 0x24>;
				clock-names = "resample_pll", "resample_src", "resample_clk";
				resample_module = <0x04>;
				status = "okay";
			};
		};
	};

	uart_A: serial@ffd24000 {
		compatible = "amlogic, meson-uart";
		reg = <0x00 0xffd24000 0x00 0x18>;
		interrupts = <0x00 0x1a 0x01>;
		status = "okay";
		clocks = <0x16 0x02 0x2e>;
		clock-names = "clk_uart", "clk_gate";
		fifosize = <0x80>;
		pinctrl-names = "default";
		pinctrl-0 = <0x27>;
	};

	uart_B: serial@ffd23000 {
		compatible = "amlogic, meson-uart";
		reg = <0x00 0xffd23000 0x00 0x18>;
		interrupts = <0x00 0x4b 0x01>;
		status = "disabled";
		clocks = <0x16 0x02 0x3c>;
		clock-names = "clk_uart", "clk_gate";
		fifosize = <0x40>;
		pinctrl-names = "default";
		pinctrl-0 = <0x28>;
	};

	uart_C: serial@ffd22000 {
		compatible = "amlogic, meson-uart";
		reg = <0x00 0xffd22000 0x00 0x18>;
		interrupts = <0x00 0x5d 0x01>;
		status = "disabled";
		clocks = <0x16 0x02 0x3c>;
		clock-names = "clk_uart", "clk_gate";
		fifosize = <0x40>;
		pinctrl-names = "default";
		pinctrl-0 = <0x29>;
	};

	vdin0: vdin0 {
		compatible = "amlogic, vdin";
		dev_name = "vdin0";
		status = "disabled";
		reserve-iomap = "true";
		flag_cma = <0x00>;
		interrupts = <0x00 0x53 0x01>;
		rdma-irq = <0x02>;
		vdin_id = <0x00>;
	};

	vdin1: vdin1 {
		compatible = "amlogic, vdin";
		dev_name = "vdin1";
		status = "disabled";
		reserve-iomap = "true";
		flag_cma = <0x00>;
		interrupts = <0x00 0x55 0x01>;
		rdma-irq = <0x04>;
		vdin_id = <0x01>;
	};

	vout {
		compatible = "amlogic, vout";
		dev_name = "vout";
		status = "okay";
	};

	vout2 {
		compatible = "amlogic, vout2";
		dev_name = "vout";
		status = "okay";
		clocks = <0x02 0xc4>, < 0x02 0xc9>;
		clock-names = "vpu_clkc0", "vpu_clkc";
	};

	vdac {
		compatible = "amlogic, vdac-g12a";
		status = "okay";
	};

	canvas: canvas {
		compatible = "amlogic, meson, canvas";
		dev_name = "amlogic-canvas";
		status = "okay";
		reg = <0x00 0xff638000 0x00 0x2000>;
	};

	ge2d {
		compatible = "amlogic, ge2d-g12a";
		dev_name = "ge2d";
		status = "okay";
		interrupts = <0x00 0x92 0x01>;
		interrupt-names = "ge2d";
		clocks = <0x02 0x95>, < 0x02 0x3d>, < 0x02 0x96>;
		clock-names = "clk_vapb_0", "clk_ge2d", "clk_ge2d_gate";
		reg = <0x00 0xff940000 0x00 0x10000>;
	};

	meson-amvideom {
		compatible = "amlogic, amvideom";
		dev_name = "amvideom";
		status = "okay";
		interrupts = <0x00 0x03 0x01>;
		interrupt-names = "vsync";
	};

	codec_io: codec_io {
		compatible = "amlogic, codec_io";
		status = "okay";
		#address-cells = <0x02>;
		#size-cells = <0x02>;
		ranges;

		io_cbus_base {
			reg = <0x00 0xffd00000 0x00 0x100000>;
		};

		io_dos_base {
			reg = <0x00 0xff620000 0x00 0x10000>;
		};

		io_hiubus_base {
			reg = <0x00 0xff63c000 0x00 0x2000>;
		};

		io_aobus_base {
			reg = <0x00 0xff800000 0x00 0x10000>;
		};

		io_vcbus_base {
			reg = <0x00 0xff900000 0x00 0x40000>;
		};

		io_dmc_base {
			reg = <0x00 0xff638000 0x00 0x2000>;
		};

		io_efuse_base {
			reg = <0x00 0xff630000 0x00 0x2000>;
		};
	};

	mesonstream {
		compatible = "amlogic, codec, streambuf";
		dev_name = "mesonstream";
		status = "okay";
		clocks = <0x02 0x40 0x02 0x39 0x02 0x43 0x02 0x22 0x02 0x0b 0x02 0xa5 0x02 0xae 0x02 0xb7 0x02 0xc0>;
		clock-names = "parser_top", "demux", "ahbarb0", "vdec", "clk_81", "clk_vdec_mux", "clk_hcodec_mux", "clk_hevc_mux", "clk_hevcb_mux";
	};

	vdec {
		compatible = "amlogic, vdec";
		dev_name = "vdec.0";
		status = "okay";
		interrupts = <0x00 0x03 0x01 0x00 0x17 0x01 0x00 0x20 0x01 0x00 0x2b 0x01 0x00 0x2c 0x01 0x00 0x2d 0x01>;
		interrupt-names = "vsync", "demux", "parser", "mailbox_0", "mailbox_1", "mailbox_2";
	};

	vcodec_dec {
		compatible = "amlogic, vcodec-dec";
		dev_name = "aml-vcodec-dec";
		status = "okay";
	};

	amvenc_avc {
		compatible = "amlogic, amvenc_avc";
		dev_name = "amvenc_avc";
		status = "okay";
		interrupts = <0x00 0x2d 0x01>;
		interrupt-names = "mailbox_2";
	};

	hevc_enc {
		compatible = "cnm, HevcEnc";
		dev_name = "HevcEnc";
		status = "okay";
		interrupts = <0x00 0xbb 0x01>;
		interrupt-names = "wave420l_irq";
		#address-cells = <0x02>;
		#size-cells = <0x02>;
		ranges;

		io_reg_base {
			reg = <0x00 0xff610000 0x00 0x4000>;
		};
	};

	rdma {
		compatible = "amlogic, meson, rdma";
		dev_name = "amlogic-rdma";
		status = "okay";
		interrupts = <0x00 0x59 0x01>;
		interrupt-names = "rdma";
	};

	meson_fb: meson-fb {
		compatible = "amlogic, meson-g12a";
		memory-region = <0x2a>;
		dev_name = "meson-fb";
		status = "okay";
		interrupts = <0x00 0x03 0x01 0x00 0x38 0x01 0x00 0x59 0x01>;
		interrupt-names = "viu-vsync", "viu2-vsync", "rdma";
		display_mode_default = "panel";
		scale_mode = <0x01>;
		display_size_default = <0x1e0 0x320 0x1e0 0x640 0x18>;
		clocks = <0x02 0xc9>;
		clock-names = "vpu_clkc";
		mem_size = <0x800000 0x1980000 0x100000 0x100000 0x800000>;
		logo_addr = "0x1f800000";
		mem_alloc = <0x01>;
		pxp_mode = <0x00>;
	};

	sd_emmc_c: emmc@ffe07000 {
		status = "okay";
		compatible = "amlogic, meson-mmc-g12a";
		reg = <0x00 0xffe07000 0x00 0x800>;
		interrupts = <0x00 0xbf 0x01>;
		pinctrl-names = "emmc_clk_cmd_pins", "emmc_all_pins";
		pinctrl-0 = <0x2b>;
		pinctrl-1 = <0x2c 0x2d>;
		clocks = <0x02 0x35>, < 0x02 0x72>, < 0x02 0x02>, < 0x02 0x05>, < 0x16>;
		clock-names = "core", "clkin0", "clkin1", "clkin2", "xtal";
		bus-width = <0x08>;
		cap-sd-highspeed;
		cap-mmc-highspeed;
		max-frequency = <0xbebc200>;
		non-removable;
		disable-wp;

		emmc {
			pinname = "emmc";
			ocr_avail = <0x200080>;
			tx_delay = <0x00>;
			co_phase = <0x03>;
			calc_f = <0x01>;
			max_req_size = <0x20000>;
			gpio_dat3 = <0x15 0x1c 0x00>;
			hw_reset = <0x15 0x25 0x00>;
			card_type = <0x01>;
			caps = "MMC_CAP_8_BIT_DATA", "MMC_CAP_MMC_HIGHSPEED", "MMC_CAP_SD_HIGHSPEED", "MMC_CAP_NONREMOVABLE", "MMC_CAP_HW_RESET", "MMC_CAP_ERASE", "MMC_CAP_CMD23";
			caps2 = "MMC_CAP2_HS200";
			f_min = <0x61a80>;
			f_max = <0xbebc200>;
		};
	};

	meson_cooldev: meson-cooldev@0 {
		status = "okay";
		compatible = "amlogic, meson-cooldev";
		device_name = "mcooldev";

		cooling_devices {

			cpufreq_cool_cluster0 {
				min_state = <0xf4240>;
				dyn_coeff = <0x73>;
				cluster_id = <0x00>;
				node_name = "cpufreq_cool0";
				device_type = "cpufreq";
			};

			cpucore_cool_cluster0 {
				min_state = <0x01>;
				dyn_coeff = <0x00>;
				cluster_id = <0x00>;
				node_name = "cpucore_cool0";
				device_type = "cpucore";
			};

			gpufreq_cool {
				min_state = <0x190>;
				dyn_coeff = <0x166>;
				gpu_pp = <0x02>;
				cluster_id = <0x00>;
				node_name = "gpufreq_cool0";
				device_type = "gpufreq";
			};

			gpucore_cool {
				min_state = <0x01>;
				dyn_coeff = <0x00>;
				cluster_id = <0x00>;
				node_name = "gpucore_cool0";
				device_type = "gpucore";
			};
		};

		cpufreq_cool0: cpufreq_cool0 {
			#cooling-cells = <0x02>;
			phandle = <0x30>;
		};

		cpucore_cool0: cpucore_cool0 {
			#cooling-cells = <0x02>;
			phandle = <0x31>;
		};

		gpufreq_cool0: gpufreq_cool0 {
			#cooling-cells = <0x02>;
			phandle = <0x32>;
		};

		gpucore_cool0: gpucore_cool0 {
			#cooling-cells = <0x02>;
			phandle = <0x33>;
		};
	};

	thermal-zones {

		soc_thermal: soc_thermal {
			polling-delay = <0x3e8>;
			polling-delay-passive = <0x64>;
			sustainable-power = <0x5b4>;
			thermal-sensors = <0x2e 0x00>;

			trips {

				pswitch_on: trip-point@0 {
					temperature = <0xea60>;
					hysteresis = <0x1388>;
					type = "passive";
				};

				pcontrol: trip-point@1 {
					temperature = <0x14c08>;
					hysteresis = <0x1388>;
					type = "passive";
					phandle = <0x2f>;
				};

				phot: trip-point@2 {
					temperature = <0x17318>;
					hysteresis = <0x1388>;
					type = "hot";
				};

				pcritical: trip-point@3 {
					temperature = <0x1adb0>;
					hysteresis = <0x3e8>;
					type = "critical";
				};
			};

			cooling-maps {

				cpufreq_cooling_map {
					trip = <0x2f>;
					cooling-device = <0x30 0x00 0x04>;
					contribution = <0x400>;
				};

				cpucore_cooling_map {
					trip = <0x2f>;
					cooling-device = <0x31 0x00 0x03>;
					contribution = <0x400>;
				};

				gpufreq_cooling_map {
					trip = <0x2f>;
					cooling-device = <0x32 0x00 0x04>;
					contribution = <0x400>;
				};

				gpucore_cooling_map {
					trip = <0x2f>;
					cooling-device = <0x33 0x00 0x02>;
					contribution = <0x400>;
				};
			};
		};

		ddr_thermal: ddr_thermal {
			polling-delay = <0x3e8>;
			polling-delay-passive = <0x64>;
			sustainable-power = <0x866>;
			thermal-sensors = <0x34 0x01>;

			trips {

				dswitch_on: trip-point@0 {
					temperature = <0xea60>;
					hysteresis = <0x1388>;
					type = "passive";
				};

				dcontrol: trip-point@1 {
					temperature = <0x124f8>;
					hysteresis = <0x1388>;
					type = "passive";
				};

				dhot: trip-point@2 {
					temperature = <0x14c08>;
					hysteresis = <0x1388>;
					type = "hot";
				};

				dcritical: trip-point@3 {
					temperature = <0x1adb0>;
					hysteresis = <0x3e8>;
					type = "critical";
				};
			};
		};

		bluetooth_thermal {
			polling-delay = <0x3a98>;
			polling-delay-passive = <0x3e8>;
			thermal-sensors = <0x35>;

			trips {

				bt_pswitchon: bt_pswitchon {
					temperature = <0xea60>;
					type = "passive";
					hysteresis = <0x3e8>;
				};

				bt_pcontrol: bt_pcontrol {
					temperature = <0x124f8>;
					hysteresis = <0x1388>;
					type = "passive";
				};

				bt_critical: bt_critical {
					temperature = <0x14c08>;
					type = "critical";
					hysteresis = <0x3e8>;
				};
			};
		};

		dram_thermal {
			polling-delay = <0x3a98>;
			polling-delay-passive = <0x3e8>;
			thermal-sensors = <0x36>;

			trips {

				dram_pswitchon: dram_pswitchon {
					temperature = <0xea60>;
					type = "passive";
					hysteresis = <0x3e8>;
				};

				dram_pcontrol: dram_pcontrol {
					temperature = <0x124f8>;
					hysteresis = <0x1388>;
					type = "passive";
				};

				dram_critical: dram_critical {
					temperature = <0x14c08>;
					type = "critical";
					hysteresis = <0x3e8>;
				};
			};
		};

		pcb_thermal {
			polling-delay = <0x3a98>;
			polling-delay-passive = <0x3e8>;
			thermal-sensors = <0x37>;

			trips {

				pcb_pswitchon: pcb_pswitchon {
					temperature = <0xea60>;
					type = "passive";
					hysteresis = <0x3e8>;
				};

				pcb_pcontrol: pcb_pcontrol {
					temperature = <0x124f8>;
					hysteresis = <0x1388>;
					type = "passive";
				};

				pcb_critical: pcb_critical {
					temperature = <0x14c08>;
					type = "critical";
					hysteresis = <0x3e8>;
				};
			};
		};
	};

	aml_snd_iomap {
		compatible = "amlogic, snd-iomap";
		status = "okay";
		#address-cells = <0x02>;
		#size-cells = <0x02>;
		ranges;

		pdm_bus {
			reg = <0x00 0xff640000 0x00 0x2000>;
		};

		audiobus_base {
			reg = <0x00 0xff642000 0x00 0x2000>;
		};

		audiolocker_base {
			reg = <0x00 0xff64a000 0x00 0x2000>;
		};

		eqdrc_base {
			reg = <0x00 0xff642800 0x00 0x1800>;
		};

		reset_base {
			reg = <0x00 0xffd01000 0x00 0x1000>;
		};
	};

	vddcpu0: pwmao_d-regulator {
		compatible = "pwm-regulator";
		pwms = <0x38 0x01 0x4e2 0x00>;
		regulator-name = "vddcpu0";
		regulator-min-microvolt = <0xb0068>;
		regulator-max-microvolt = <0xf9830>;
		regulator-always-on;
		max-duty-cycle = <0x4e2>;
		voltage-table = <0xf9830 0x00>, <0xf6d38 0x03>, <0xf4628 0x06>, <0xf1f18 0x0a>, <0xef808 0x0d>, <0xed0f8 0x10>, <0xea9e8 0x14>, <0xe82d8 0x17>, <0xe5bc8 0x1a>, <0xe34b8 0x1e>, <0xe0da8 0x21>, <0xde698 0x24>, <0xdbf88 0x28>, <0xd9878 0x2b>, <0xd7168 0x2e>, <0xd4a58 0x32>, <0xd2348 0x35>, <0xcfc38 0x38>, <0xcd528 0x3c>, <0xcae18 0x3f>, <0xc8708 0x43>, <0xc5ff8 0x46>, <0xc38e8 0x49>, <0xc11d8 0x4c>, <0xbeac8 0x50>, <0xbc3b8 0x53>, <0xb9ca8 0x56>, <0xb7598 0x5a>, <0xb4e88 0x5d>, <0xb2778 0x60>, <0xb0068 0x64>;
		status = "okay";
		phandle = <0x10>;
	};

	ddr_bandwidth {
		compatible = "amlogic, ddr-bandwidth";
		status = "okay";
		reg = <0x00 0xff638000 0x00 0x100 0x00 0xff638c00 0x00 0x100>;
		interrupts = <0x00 0x34 0x01>;
		interrupt-names = "ddr_bandwidth";
	};

	dmc_monitor {
		compatible = "amlogic, dmc_monitor";
		status = "okay";
		reg_base = <0xff639000>;
		interrupts = <0x00 0x33 0x01>;
	};

	defendkey: defendkey {
		compatible = "amlogic, defendkey";
		reg = <0x00 0xff630218 0x00 0x04>;
		mem_size = <0x00 0x100000>;
		status = "okay";
	};

	aml_dma {
		compatible = "amlogic,aml_txlx_dma";
		reg = <0x00 0xff63e000 0x00 0x48>;
		interrupts = <0x00 0xb4 0x01>;

		aml_aes {
			compatible = "amlogic,aes_g12a_dma";
			dev_name = "aml_aes_dma";
			status = "okay";
		};

		aml_sha {
			compatible = "amlogic,sha_dma";
			dev_name = "aml_sha_dma";
			status = "okay";
		};

		aml_tdes {
			compatible = "amlogic,tdes_dma";
			dev_name = "aml_tdes_dma";
			status = "okay";
		};
	};

	rng {
		compatible = "amlogic,meson-rng";
		status = "okay";
		#address-cells = <0x02>;
		#size-cells = <0x02>;
		reg = <0x00 0xff630218 0x00 0x04>;
		quality = /bits/ 16 <0x3e8>;
	};

	efuse: efuse {
		compatible = "amlogic, efuse";
		read_cmd = <0x82000030>;
		write_cmd = <0x82000031>;
		get_max_cmd = <0x82000033>;
		key = <0x39>;
		clocks = <0x02 0x61>;
		clock-names = "efuse_clk";
		status = "okay";
	};

	cpu_ver_name {
		compatible = "amlogic, cpu-major-id-g12a";
	};

	partitions: partitions {
		parts = <0x0c>;
		part-0 = <0x3a>;
		part-1 = <0x3b>;
		part-2 = <0x3c>;
		part-3 = <0x3d>;
		part-4 = <0x3e>;
		part-5 = <0x3f>;
		part-6 = <0x40>;
		part-7 = <0x41>;
		part-8 = <0x42>;
		part-9 = <0x43>;
		part-10 = <0x44>;
		part-11 = <0x45>;

		logo: logo {
			pname = "logo";
			size = <0x00 0x800000>;
			mask = <0x01>;
			phandle = <0x3a>;
		};

		dtbo_a: dtbo_a {
			pname = "dtbo_a";
			size = <0x00 0x400000>;
			mask = <0x01>;
			phandle = <0x3b>;
		};

		dtbo_b: dtbo_b {
			pname = "dtbo_b";
			size = <0x00 0x400000>;
			mask = <0x01>;
			phandle = <0x3c>;
		};

		vbmeta_a: vbmeta_a {
			pname = "vbmeta_a";
			size = <0x00 0x100000>;
			mask = <0x01>;
			phandle = <0x3d>;
		};

		vbmeta_b: vbmeta_b {
			pname = "vbmeta_b";
			size = <0x00 0x100000>;
			mask = <0x01>;
			phandle = <0x3e>;
		};

		boot_a: boot_a {
			pname = "boot_a";
			size = <0x00 0x1000000>;
			mask = <0x01>;
			phandle = <0x3f>;
		};

		boot_b: boot_b {
			pname = "boot_b";
			size = <0x00 0x1000000>;
			mask = <0x01>;
			phandle = <0x40>;
		};

		system_a: system_a {
			pname = "system_a";
			size = <0x00 0x2040b000>;
			mask = <0x01>;
			phandle = <0x41>;
		};

		system_b: system_b {
			pname = "system_b";
			size = <0x00 0x2040b000>;
			mask = <0x01>;
			phandle = <0x42>;
		};

		misc: misc {
			pname = "misc";
			size = <0x00 0x800000>;
			mask = <0x01>;
			phandle = <0x43>;
		};

		settings: settings {
			pname = "settings";
			size = <0x00 0x10000000>;
			mask = <0x01>;
			phandle = <0x44>;
		};

		data: data {
			pname = "data";
			size = <0xffffffff 0xffffffff>;
			mask = <0x04>;
			phandle = <0x45>;
		};
	};

	firmware {

		android {
			compatible = "android,firmware";

			vbmeta {
				compatible = "android,vbmeta";
				parts = "boot,system";
				by_name_prefix = "/dev/block";
			};

			fstab {
				compatible = "android,fstab";

				system {
					compatible = "android,system";
					dev = "/dev/block/system";
					type = "ext4";
					mnt_flags = "ro,barrier=1,inode_readahead_blks=8";
					fsmgr_flags = "wait,slotselect";
				};
			};
		};
	};

	lcd: lcd {
		compatible = "amlogic, lcd-g12a";
		mode = "tablet";
		status = "okay";
		key_valid = <0x00>;
		clocks = <0x02 0x24 0x02 0x31 0x02 0x9a 0x02 0x5d 0x02 0x5f 0x02 0x07>;
		clock-names = "dsi_host_gate", "dsi_phy_gate", "dsi_meas", "encl_top_gate", "encl_int_gate", "gp0_pll";
		reg = <0x00 0xffd07000 0x00 0x400 0x00 0xff644000 0x00 0x200>;
		interrupts = <0x00 0x03 0x01 0x00 0x38 0x01>;
		interrupt-names = "vsync", "vsync2";
		pinctrl_version = <0x02>;
		lcd_cpu-gpios = <0x15 0x05 0x00>;
		lcd_cpu_gpio_names = "GPIOZ_5";

		lcd_0 {
			model_name = "B080XAN01";
			interface = "mipi";
			basic_setting = <0x300 0x400 0x3b4 0x474 0x08 0x77 0x9f>;
			lcd_timing = <0x40 0x38 0x00 0x32 0x1e 0x00>;
			clk_attr = <0x00 0x00 0x01 0x3dd6dc0>;
			mipi_attr = <0x04 0x226 0x00 0x01 0x00 0x02 0x01 0x00>;
			dsi_init_on = <0x05 0x01 0x11 0xfd 0x01 0x14 0x05 0x01 0x29 0xfd 0x01 0x14 0xff 0x00>;
			dsi_init_off = <0x05 0x01 0x28 0xfd 0x01 0x0a 0x05 0x01 0x10 0xfd 0x01 0x0a 0xff 0x00>;
			extern_init = <0xff>;
			power_on_step = <0x00 0x01 0x00 0x64 0x00 0x00 0x00 0x0a 0x00 0x00 0x01 0x14 0x02 0x00 0x00 0x00 0xff 0x00 0x00 0x00>;
			power_off_step = <0x02 0x00 0x00 0x32 0x00 0x00 0x00 0x0a 0x00 0x01 0x01 0x64 0xff 0x00 0x00 0x00>;
			backlight_index = <0x00>;
		};

		lcd_1 {
			model_name = "TV070WSM";
			interface = "mipi";
			basic_setting = <0x258 0x400 0x2bc 0x41d 0x08 0x5f 0xa3>;
			lcd_timing = <0x18 0x24 0x00 0x02 0x08 0x00>;
			clk_attr = <0x00 0x00 0x01 0x2a33390>;
			mipi_attr = <0x04 0x168 0x00 0x01 0x00 0x02 0x00 0x00>;
			dsi_init_on = <0xff 0x0a 0xf0 0x03 0x00 0x01 0x1e 0xf0 0x03 0x00 0x00 0x0a 0xf0 0x03 0x00 0x01 0x1e 0xfc 0x02 0x04 0x03 0xff 0x00>;
			dsi_init_off = <0xff 0x00>;
			extern_init = <0x01>;
			power_on_step = <0x00 0x01 0x00 0xc8 0x02 0x00 0x00 0x00 0xff 0x00 0x00 0x00>;
			power_off_step = <0x02 0x00 0x00 0x00 0x00 0x00 0x00 0x14 0x00 0x01 0x01 0x64 0xff 0x00 0x00 0x00>;
			backlight_index = <0x00>;
		};

		lcd_2 {
			model_name = "P070ACB";
			interface = "mipi";
			basic_setting = <0x258 0x400 0x2a8 0x4aa 0x08 0x03 0x05>;
			lcd_timing = <0x18 0x24 0x00 0x0a 0x50 0x00>;
			clk_attr = <0x00 0x00 0x01 0x2e755c0>;
			mipi_attr = <0x04 0x190 0x00 0x01 0x00 0x02 0x00 0x00>;
			dsi_init_on = <0xff 0x0a 0xf0 0x03 0x00 0x01 0x1e 0xf0 0x03 0x00 0x00 0x0a 0xf0 0x03 0x00 0x01 0x1e 0xfc 0x02 0x04 0x03 0xff 0x00>;
			dsi_init_off = <0xff 0x00>;
			extern_init = <0x02>;
			power_on_step = <0x00 0x01 0x00 0xc8 0x02 0x00 0x00 0x00 0xff 0x00 0x00 0x00>;
			power_off_step = <0x02 0x00 0x00 0x00 0x00 0x00 0x00 0x14 0x00 0x01 0x01 0x64 0xff 0x00 0x00 0x00>;
			backlight_index = <0x00>;
		};

		lcd_3 {
			model_name = "TL050FHV02CT";
			interface = "mipi";
			basic_setting = <0x438 0x780 0x465 0x834 0x08 0x41 0x77>;
			lcd_timing = <0x05 0x1e 0x00 0x2c 0x6c 0x00>;
			clk_attr = <0x00 0x00 0x01 0x70a71c8>;
			mipi_attr = <0x04 0x3c0 0x00 0x01 0x00 0x02 0x01 0x00>;
			dsi_init_on = <0xff 0x00>;
			dsi_init_off = <0xff 0x00>;
			extern_init = <0x03>;
			power_on_step = <0x00 0x01 0x00 0xc8 0x00 0x00 0x01 0x14 0x00 0x00 0x00 0x0a 0x00 0x00 0x01 0x14 0x02 0x00 0x00 0x00 0xff 0x00 0x00 0x00>;
			power_off_step = <0x02 0x00 0x00 0x00 0x00 0x00 0x00 0x14 0x00 0x01 0x01 0x64 0xff 0x00 0x00 0x00>;
			backlight_index = <0x00>;
		};

		lcd_4 {
			model_name = "TL070WSH27";
			interface = "mipi";
			basic_setting = <0x400 0x258 0x4e2 0x276 0x08 0x9a 0x56>;
			lcd_timing = <0x50 0x64 0x00 0x05 0x14 0x00>;
			clk_attr = <0x00 0x00 0x01 0x2d0fa50>;
			mipi_attr = <0x04 0x12c 0x00 0x01 0x00 0x02 0x01 0x00>;
			dsi_init_on = <0x05 0x01 0x11 0xfd 0x01 0x14 0x05 0x01 0x29 0xfd 0x01 0x14 0xff 0x00>;
			dsi_init_off = <0x05 0x01 0x28 0xfd 0x01 0x0a 0x05 0x01 0x10 0xfd 0x01 0x0a 0xff 0x00>;
			extern_init = <0xff>;
			power_on_step = <0x00 0x01 0x00 0x64 0x00 0x00 0x00 0x0a 0x00 0x00 0x01 0x14 0x02 0x00 0x00 0x00 0xff 0x00 0x00 0x00>;
			power_off_step = <0x02 0x00 0x00 0x32 0x00 0x00 0x00 0x0a 0x00 0x01 0x01 0x64 0xff 0x00 0x00 0x00>;
			backlight_index = <0x00>;
		};

		lcd_5 {
			model_name = "TV070WSM_FT";
			interface = "mipi";
			basic_setting = <0x258 0x400 0x2bc 0x41d 0x08 0x5f 0xa3>;
			lcd_timing = <0x18 0x24 0x00 0x02 0x08 0x00>;
			clk_attr = <0x00 0x00 0x01 0x2a33390>;
			mipi_attr = <0x04 0x168 0x00 0x01 0x00 0x02 0x00 0x00>;
			dsi_init_on = <0xff 0x0a 0xf0 0x03 0x00 0x01 0x1e 0xf0 0x03 0x00 0x00 0x0a 0xf0 0x03 0x00 0x01 0x1e 0xfc 0x02 0x04 0x03 0xff 0x00>;
			dsi_init_off = <0xff 0x00>;
			extern_init = <0x04>;
			power_on_step = <0x00 0x01 0x00 0xc8 0x02 0x00 0x00 0x00 0xff 0x00 0x00 0x00>;
			power_off_step = <0x02 0x00 0x00 0x00 0x00 0x00 0x00 0x14 0x00 0x01 0x01 0x64 0xff 0x00 0x00 0x00>;
			backlight_index = <0x00>;
		};

		lcd_6 {
			model_name = "P070ACB_FT";
			interface = "mipi";
			basic_setting = <0x258 0x400 0x302 0x42e 0x08 0x03 0x05>;
			lcd_timing = <0x0a 0x50 0x00 0x06 0x14 0x00>;
			clk_attr = <0x00 0x00 0x01 0x2f24d90>;
			mipi_attr = <0x04 0x190 0x00 0x01 0x00 0x02 0x00 0x00>;
			dsi_init_on = <0xff 0x0a 0xf0 0x03 0x00 0x01 0x1e 0xf0 0x03 0x00 0x00 0x0a 0xf0 0x03 0x00 0x01 0x1e 0xfc 0x02 0x04 0x03 0xff 0x00>;
			dsi_init_off = <0xff 0x00>;
			extern_init = <0x05>;
			power_on_step = <0x00 0x01 0x00 0xc8 0x02 0x00 0x00 0x00 0xff 0x00 0x00 0x00>;
			power_off_step = <0x02 0x00 0x00 0x00 0x00 0x00 0x00 0x14 0x00 0x01 0x01 0x64 0xff 0x00 0x00 0x00>;
			backlight_index = <0x00>;
		};

		lcd_7 {
			model_name = "ILI9806E";
			interface = "mipi";
			basic_setting = <0x1e0 0x320 0x276 0x344 0x10 0x33 0x56>;
			lcd_timing = <0x0a 0x32 0x00 0x04 0x14 0x00>;
			clk_attr = <0x00 0x00 0x01 0x1e230a0>;
			mipi_attr = <0x02 0x00 0x00 0x01 0x00 0x02 0x01 0x00>;
			dsi_init_on = <0x05 0x01 0x11 0xfd 0x01 0x78 0x05 0x01 0x29 0xff 0xff>;
			dsi_init_off = <0x05 0x01 0x28 0xfd 0x01 0x0a 0x05 0x01 0x10 0xff 0xff>;
			extern_init = <0x06>;
			power_on_step = <0x00 0x00 0x01 0x01 0x00 0x00 0x00 0x0a 0x00 0x00 0x01 0x78 0x02 0x00 0x00 0xc8 0xff 0x00 0x00 0x00>;
			power_off_step = <0x02 0x00 0x00 0x96 0x00 0x00 0x00 0x78 0xff 0x00 0x00 0x00>;
			backlight_index = <0x00>;
		};

		lcd_8 {
			model_name = "ST7701S";
			interface = "mipi";
			basic_setting = <0x1e0 0x320 0x226 0x34e 0x10 0x34 0x56>;
			lcd_timing = <0x0a 0x1e 0x00 0x06 0x14 0x00>;
			clk_attr = <0x00 0x00 0x01 0x1a9feb0>;
			mipi_attr = <0x02 0x2a0 0x00 0x01 0x00 0x02 0x01 0x00>;
			dsi_init_on = <0x05 0x01 0x11 0xfd 0x01 0x78 0x05 0x01 0x29 0xff 0xff>;
			dsi_init_off = <0x05 0x01 0x28 0xfd 0x01 0x0a 0x05 0x01 0x10 0xff 0xff>;
			extern_init = <0x07>;
			power_on_step = <0x00 0x00 0x01 0x01 0x00 0x00 0x00 0x0a 0x00 0x00 0x01 0x78 0x02 0x00 0x00 0xc8 0xff 0x00 0x00 0x00>;
			power_off_step = <0x02 0x00 0x00 0x96 0x00 0x00 0x00 0x78 0xff 0x00 0x00 0x00>;
			backlight_index = <0x00>;
		};

		lcd_9 {
			model_name = "ST7701S_wily";
			interface = "mipi";
			basic_setting = <0x1e0 0x320 0x28c 0x348 0x10 0x34 0x56>;
			lcd_timing = <0x0c 0x50 0x00 0x04 0x12 0x00>;
			clk_attr = <0x00 0x00 0x01 0x1e230a0>;
			mipi_attr = <0x02 0x2a0 0x00 0x01 0x00 0x02 0x01 0x00>;
			dsi_init_on = <0x05 0x01 0x11 0xfd 0x01 0x78 0x05 0x01 0x29 0xff 0xff>;
			dsi_init_off = <0x05 0x01 0x28 0xfd 0x01 0x0a 0x05 0x01 0x10 0xff 0xff>;
			extern_init = <0x08>;
			power_on_step = <0x00 0x00 0x01 0x01 0x00 0x00 0x00 0x0a 0x00 0x00 0x01 0x78 0x02 0x00 0x00 0xc8 0xff 0x00 0x00 0x00>;
			power_off_step = <0x02 0x00 0x00 0x96 0x00 0x00 0x00 0x78 0xff 0x00 0x00 0x00>;
			backlight_index = <0x00>;
		};

		lcd_10 {
			model_name = "ST7701S_holitech";
			interface = "mipi";
			basic_setting = <0x1e0 0x320 0x226 0x34c 0x10 0x34 0x56>;
			lcd_timing = <0x0a 0x1e 0x00 0x04 0x14 0x00>;
			clk_attr = <0x00 0x00 0x01 0x1ab3f00>;
			mipi_attr = <0x02 0x2a0 0x00 0x01 0x00 0x02 0x01 0x00>;
			dsi_init_on = <0x05 0x01 0x11 0xfd 0x01 0x78 0x05 0x01 0x29 0xff 0xff>;
			dsi_init_off = <0x05 0x01 0x28 0xfd 0x01 0x0a 0x05 0x01 0x10 0xff 0xff>;
			extern_init = <0x09>;
			power_on_step = <0x00 0x00 0x01 0x01 0x00 0x00 0x00 0x0a 0x00 0x00 0x01 0x78 0x02 0x00 0x00 0xc8 0xff 0x00 0x00 0x00>;
			power_off_step = <0x02 0x00 0x00 0x96 0x00 0x00 0x00 0x78 0xff 0x00 0x00 0x00>;
			backlight_index = <0x00>;
		};
	};

	lcd_extern {
		compatible = "amlogic, lcd_extern";
		status = "okay";
		i2c_bus = "i2c_bus_0";
		key_valid = <0x00>;

		extern_0 {
			index = <0x00>;
			extern_name = "mipi_default";
			status = "okay";
			type = <0x02>;
			cmd_size = <0xff>;
			init_on = <0xfd 0x01 0x0a 0x05 0x01 0x11 0xfd 0x01 0x78 0x05 0x01 0x29 0xff 0x00>;
			init_off = <0x05 0x01 0x28 0xfd 0x01 0x0a 0x05 0x01 0x10 0xfd 0x01 0x96 0xff 0x00>;
		};

		extern_1 {
			index = <0x01>;
			extern_name = "mipi_default";
			status = "okay";
			type = <0x02>;
			cmd_size = <0xff>;
			init_on = <0xfd 0x01 0x0a 0x15 0x02 0x62 0x01 0x39 0x05 0xff 0xaa 0x55 0x25 0x01 0x15 0x02 0xfc 0x08 0xfd 0x01 0x01 0x15 0x02 0xfc 0x00 0x39 0x05 0xff 0xaa 0x55 0x25 0x00 0xfd 0x01 0x14 0x39 0x06 0xf0 0x55 0xaa 0x52 0x08 0x00 0x39 0x03 0xb1 0x68 0x41 0x15 0x02 0xb5 0x88 0x15 0x02 0xb6 0x0f 0x39 0x05 0xb8 0x01 0x01 0x12 0x01 0x39 0x03 0xbb 0x11 0x11 0x39 0x03 0xbc 0x05 0x05 0x15 0x02 0xc7 0x03 0x39 0x06 0xbd 0x03 0x02 0x19 0x17 0x00 0x15 0x02 0xc8 0x80 0x39 0x06 0xf0 0x55 0xaa 0x52 0x08 0x01 0x39 0x03 0xb2 0x01 0x01 0x39 0x03 0xb3 0x28 0x28 0x39 0x03 0xb4 0x14 0x14 0x39 0x03 0xb8 0x05 0x05 0x39 0x03 0xb9 0x45 0x45 0x39 0x03 0xba 0x25 0x25 0x39 0x03 0xbc 0x88 0x00 0x39 0x03 0xbd 0x88 0x00 0x39 0x06 0xf0 0x55 0xaa 0x52 0x08 0x02 0x15 0x02 0xee 0x00 0x39 0x11 0xb0 0x00 0x4b 0x00 0x5c 0x00 0x79 0x00 0x94 0x00 0xa6 0x00 0xd8 0x00 0xf2 0x01 0x19 0x39 0x11 0xb1 0x01 0x39 0x01 0x77 0x01 0xa2 0x01 0xf2 0x02 0x32 0x02 0x34 0x02 0x6d 0x02 0xa2 0x39 0x11 0xb2 0x02 0xc7 0x02 0xf2 0x03 0x18 0x03 0x43 0x03 0x65 0x03 0x86 0x03 0x8f 0x03 0x94 0x39 0x05 0xb3 0x03 0x96 0x03 0x98 0x39 0x11 0xb4 0x00 0x84 0x00 0x91 0x00 0xa4 0x00 0xb6 0x00 0xca 0x00 0xe9 0x01 0x02 0x01 0x2a 0x39 0x11 0xb5 0x01 0x49 0x01 0x82 0x01 0xaf 0x01 0xf7 0x02 0x36 0x02 0x38 0x02 0x70 0x02 0xa6 0x39 0x11 0xb6 0x02 0xc8 0x02 0xf5 0x03 0x1a 0x03 0x43 0x03 0x62 0x03 0x82 0x03 0x8f 0x03 0x94 0x39 0x05 0xb7 0x03 0x96 0x03 0x98 0x39 0x11 0xb8 0x01 0x22 0x01 0x27 0x01 0x2e 0x01 0x38 0x01 0x40 0x01 0x53 0x01 0x60 0x01 0x7b 0x39 0x11 0xb9 0x01 0x8c 0x01 0xb5 0x01 0xd3 0x02 0x11 0x02 0x49 0x02 0x4a 0x02 0x7f 0x02 0xb1 0x39 0x11 0xba 0x02 0xd1 0x03 0x00 0x03 0x22 0x03 0x49 0x03 0x60 0x03 0x7a 0x03 0x8b 0x03 0x8f 0x39 0x05 0xbb 0x03 0x93 0x03 0x9a 0x39 0x11 0xbc 0x00 0x37 0x00 0x48 0x00 0x65 0x00 0x80 0x00 0x92 0x00 0xc4 0x00 0xde 0x01 0x05 0x39 0x11 0xbd 0x01 0x31 0x01 0x6f 0x01 0x9e 0x01 0xee 0x02 0x32 0x02 0x34 0x02 0x71 0x02 0xa7 0x39 0x11 0xbe 0x02 0xd3 0x02 0xfe 0x03 0x24 0x03 0x4f 0x03 0x71 0x03 0x92 0x03 0x9b 0x03 0xa0 0x39 0x05 0xbf 0x03 0xa6 0x03 0xa8 0x39 0x11 0xc0 0x00 0x70 0x00 0x7d 0x00 0x90 0x00 0xa4 0x00 0xb6 0x00 0xd5 0x00 0xee 0x01 0x16 0x39 0x11 0xc1 0x01 0x41 0x01 0x7a 0x01 0xab 0x01 0xf3 0x02 0x36 0x02 0x38 0x02 0x74 0x02 0xaa 0x39 0x11 0xc2 0x02 0xd4 0x03 0x01 0x03 0x26 0x03 0x4f 0x03 0x6e 0x03 0x8e 0x03 0x9b 0x03 0xa0 0x39 0x05 0xc3 0x03 0xa6 0x03 0xa8 0x39 0x11 0xc4 0x01 0x0e 0x01 0x13 0x01 0x1a 0x01 0x24 0x01 0x2c 0x01 0x3f 0x01 0x4c 0x01 0x67 0x39 0x11 0xc5 0x01 0x84 0x01 0xad 0x01 0xcf 0x02 0x0d 0x02 0x49 0x02 0x4a 0x02 0x83 0x02 0xb5 0x39 0x11 0xc6 0x02 0xdd 0x03 0x0c 0x03 0x2e 0x03 0x55 0x03 0x6b 0x03 0x86 0x03 0x97 0x03 0x9b 0x39 0x05 0xc7 0x03 0xa1 0x03 0xa8 0x39 0x06 0xf0 0x55 0xaa 0x52 0x08 0x04 0x39 0x06 0xb1 0x03 0x02 0x02 0x02 0x00 0x39 0x06 0xf0 0x55 0xaa 0x52 0x08 0x06 0x39 0x03 0xb0 0x11 0x11 0x39 0x03 0xb1 0x13 0x13 0x39 0x03 0xb2 0x03 0x03 0x39 0x03 0xb3 0x34 0x34 0x39 0x03 0xb4 0x34 0x34 0x39 0x03 0xb5 0x34 0x34 0x39 0x03 0xb6 0x34 0x34 0x39 0x03 0xb7 0x34 0x34 0x39 0x03 0xb8 0x34 0x34 0x39 0x03 0xb9 0x34 0x34 0x39 0x03 0xba 0x34 0x34 0x39 0x03 0xbb 0x34 0x34 0x39 0x03 0xbc 0x34 0x34 0x39 0x03 0xbd 0x34 0x34 0x39 0x03 0xbe 0x34 0x34 0x39 0x03 0xbf 0x34 0x34 0x39 0x03 0xc0 0x34 0x34 0x39 0x03 0xc1 0x02 0x02 0x39 0x03 0xc2 0x12 0x12 0x39 0x03 0xc3 0x10 0x10 0x39 0x03 0xe5 0x34 0x34 0x39 0x06 0xd8 0x00 0x00 0x00 0x00 0x00 0x39 0x06 0xd9 0x00 0x00 0x00 0x00 0x00 0x39 0x06 0xf0 0x55 0xaa 0x52 0x08 0x05 0x15 0x02 0xc0 0x03 0x15 0x02 0xc1 0x02 0x39 0x03 0xc8 0x01 0x20 0x15 0x02 0xe5 0x03 0x15 0x02 0xe6 0x03 0x15 0x02 0xe7 0x03 0x15 0x02 0xe8 0x03 0x15 0x02 0xe9 0x03 0x39 0x05 0xd1 0x03 0x00 0x3d 0x00 0x39 0x06 0xf0 0x55 0xaa 0x52 0x08 0x03 0x39 0x03 0xb0 0x11 0x00 0x39 0x03 0xb1 0x11 0x00 0x39 0x06 0xb2 0x03 0x00 0x00 0x00 0x00 0x39 0x06 0xb3 0x03 0x00 0x00 0x00 0x00 0x39 0x06 0xba 0x31 0x00 0x00 0x00 0x00 0x15 0x02 0x35 0x00 0x15 0x02 0x51 0xff 0x15 0x02 0x53 0x2c 0x15 0x02 0x55 0x03 0x05 0x01 0x11 0xfd 0x01 0x78 0x05 0x01 0x29 0xfd 0x01 0x82 0xff 0x00>;
			init_off = <0x05 0x01 0x28 0xfd 0x01 0x0a 0x05 0x01 0x10 0xfd 0x01 0x96 0xff 0x00>;
		};

		extern_2 {
			index = <0x02>;
			extern_name = "mipi_default";
			status = "okay";
			type = <0x02>;
			cmd_size = <0xff>;
			init_on = <0x29 0x05 0xff 0xaa 0x55 0x25 0x01 0x23 0x02 0xfc 0x08 0xfd 0x01 0x01 0x23 0x02 0xfc 0x00 0xfd 0x01 0x01 0x23 0x02 0x6f 0x21 0x23 0x02 0xf7 0x01 0xfd 0x01 0x01 0x23 0x02 0x6f 0x21 0x23 0x02 0xf7 0x00 0xfd 0x01 0x01 0x23 0x02 0x6f 0x1a 0x23 0x02 0xf7 0x05 0xfd 0x01 0x01 0x29 0x05 0xff 0xaa 0x55 0x25 0x00 0x29 0x06 0xf0 0x55 0xaa 0x52 0x08 0x00 0x29 0x03 0xb1 0x68 0x41 0x23 0x02 0xb5 0x88 0x29 0x06 0xbd 0x02 0xb0 0x0c 0x14 0x00 0x23 0x02 0xc8 0x80 0x29 0x06 0xf0 0x55 0xaa 0x52 0x08 0x01 0x29 0x03 0xb3 0x2d 0x2d 0x29 0x03 0xb4 0x19 0x19 0x23 0x02 0xb5 0x06 0x29 0x03 0xb9 0x36 0x36 0x29 0x03 0xba 0x26 0x26 0x29 0x03 0xbc 0xa8 0x01 0x29 0x03 0xbd 0xab 0x01 0x23 0x02 0xc0 0x0c 0x29 0x06 0xf0 0x55 0xaa 0x52 0x08 0x02 0x23 0x02 0xee 0x02 0x29 0x07 0xb0 0x00 0x50 0x00 0x52 0x00 0x73 0x23 0x02 0x6f 0x06 0x29 0x07 0xb0 0x00 0x8f 0x00 0xa5 0x00 0xca 0x23 0x02 0x6f 0x0c 0x29 0x05 0xb0 0x00 0xea 0x01 0x1b 0x29 0x07 0xb1 0x01 0x42 0x01 0x82 0x01 0xb3 0x23 0x02 0x6f 0x06 0x29 0x07 0xb1 0x02 0x00 0x02 0x41 0x02 0x42 0x23 0x02 0x6f 0x0c 0x29 0x05 0xb1 0x02 0x78 0x02 0xb5 0x29 0x07 0xb2 0x02 0xda 0x03 0x12 0x03 0x3a 0x23 0x02 0x6f 0x06 0x29 0x07 0xb2 0x03 0x6e 0x03 0x8d 0x03 0xb1 0x23 0x02 0x6f 0x0c 0x29 0x05 0xb2 0x03 0xca 0x03 0xe8 0x29 0x05 0xb3 0x03 0xf4 0x03 0xff 0x29 0x07 0xbc 0x00 0x05 0x00 0x52 0x00 0x73 0x23 0x02 0x6f 0x06 0x29 0x07 0xbc 0x00 0x8f 0x00 0xa5 0x00 0xca 0x23 0x02 0x6f 0x0c 0x29 0x05 0xbc 0x00 0xea 0x01 0x1b 0x29 0x07 0xbd 0x01 0x42 0x01 0x82 0x01 0xb3 0x23 0x02 0x6f 0x06 0x29 0x07 0xbd 0x02 0x00 0x02 0x41 0x02 0x42 0x23 0x02 0x6f 0x0c 0x29 0x05 0xbd 0x02 0x78 0x02 0xb5 0x29 0x07 0xbe 0x02 0xda 0x03 0x12 0x03 0x3a 0x23 0x02 0x6f 0x06 0x29 0x07 0xbe 0x03 0x6e 0x03 0x8d 0x03 0xb1 0x23 0x02 0x6f 0x0c 0x29 0x05 0xbe 0x03 0xca 0x03 0xe8 0x29 0x05 0xbf 0x03 0xf4 0x03 0xff 0x29 0x06 0xf0 0x55 0xaa 0x52 0x08 0x03 0x29 0x06 0xb2 0x05 0x00 0x00 0x00 0x00 0x29 0x06 0xb6 0x05 0x00 0x00 0x00 0x00 0x29 0x06 0xb7 0x05 0x00 0x00 0x00 0x00 0x29 0x06 0xba 0x57 0x00 0x00 0x00 0x00 0x29 0x06 0xbb 0x57 0x00 0x00 0x00 0x00 0x29 0x05 0xc0 0x00 0x34 0x00 0x00 0x29 0x05 0xc1 0x00 0x00 0x34 0x00 0x23 0x02 0xc4 0x40 0x29 0x06 0xf0 0x55 0xaa 0x52 0x08 0x05 0x29 0x03 0xb0 0x17 0x06 0x29 0x03 0xb1 0x17 0x06 0x29 0x03 0xb2 0x17 0x06 0x29 0x03 0xb3 0x17 0x06 0x29 0x03 0xb4 0x17 0x06 0x29 0x06 0xbd 0x03 0x01 0x03 0x03 0x01 0x23 0x02 0xc0 0x05 0x23 0x02 0xc4 0x82 0x23 0x02 0xc5 0xa2 0x29 0x03 0xc8 0x03 0x30 0x29 0x03 0xc9 0x03 0x31 0x29 0x04 0xcc 0x00 0x00 0x3c 0x29 0x04 0xcd 0x00 0x00 0x3c 0x29 0x06 0xd1 0x00 0x44 0x09 0x00 0x00 0x29 0x06 0xd2 0x00 0x04 0x0b 0x00 0x00 0x29 0x06 0xf0 0x55 0xaa 0x52 0x08 0x06 0x29 0x03 0xb0 0x0b 0x2d 0x29 0x03 0xb1 0x2d 0x09 0x29 0x03 0xb2 0x2a 0x29 0x29 0x03 0xb3 0x34 0x1b 0x29 0x03 0xb4 0x19 0x17 0x29 0x03 0xb5 0x15 0x13 0x29 0x03 0xb6 0x11 0x01 0x29 0x03 0xb7 0x34 0x34 0x29 0x03 0xb8 0x34 0x2d 0x29 0x03 0xb9 0x2d 0x34 0x29 0x03 0xba 0x2d 0x2d 0x29 0x03 0xbb 0x34 0x34 0x29 0x03 0xbc 0x34 0x34 0x29 0x03 0xbd 0x00 0x10 0x29 0x03 0xbe 0x12 0x14 0x29 0x03 0xbf 0x16 0x18 0x29 0x03 0xc0 0x1a 0x34 0x29 0x03 0xc1 0x29 0x2a 0x29 0x03 0xc2 0x08 0x2d 0x29 0x03 0xc3 0x2d 0x0a 0x29 0x03 0xc4 0x0a 0x2d 0x29 0x03 0xc5 0x2d 0x00 0x29 0x03 0xc6 0x2a 0x29 0x29 0x03 0xc7 0x34 0x14 0x29 0x03 0xc8 0x16 0x18 0x29 0x03 0xc9 0x1a 0x10 0x29 0x03 0xca 0x12 0x08 0x29 0x03 0xcb 0x34 0x34 0x29 0x03 0xcc 0x34 0x2d 0x29 0x03 0xcd 0x2d 0x34 0x29 0x03 0xce 0x2d 0x2d 0x29 0x03 0xcf 0x34 0x34 0x29 0x03 0xd0 0x34 0x34 0x29 0x03 0xd1 0x09 0x13 0x29 0x03 0xd2 0x11 0x1b 0x29 0x03 0xd3 0x19 0x17 0x29 0x03 0xd4 0x15 0x34 0x29 0x03 0xd5 0x29 0x2a 0x29 0x03 0xd6 0x01 0x2d 0x29 0x03 0xd7 0x2d 0x0b 0x29 0x06 0xd8 0x00 0x00 0x00 0x00 0x00 0x29 0x06 0xd9 0x00 0x00 0x00 0x00 0x00 0x29 0x03 0xe5 0x34 0x34 0x29 0x03 0xe6 0x34 0x34 0x23 0x02 0xe7 0x00 0x29 0x03 0xe8 0x34 0x34 0x29 0x03 0xe9 0x34 0x34 0x23 0x02 0xea 0x00 0x29 0x06 0xf0 0x55 0xaa 0x52 0x00 0x00 0x13 0x01 0x35 0x13 0x01 0x11 0xfd 0x01 0x78 0x13 0x01 0x29 0xfd 0x01 0x14 0xff 0x00>;
			init_off = <0x05 0x01 0x28 0xfd 0x01 0x0a 0x05 0x01 0x10 0xfd 0x01 0x96 0xff 0x00>;
		};

		extern_3 {
			index = <0x03>;
			extern_name = "mipi_default";
			status = "okay";
			type = <0x02>;
			cmd_size = <0xff>;
			init_on = <0x29 0x06 0xf0 0x55 0xaa 0x52 0x08 0x03 0x29 0x0a 0x90 0x03 0x14 0x09 0x00 0x00 0x00 0x38 0x00 0x00 0x29 0x0a 0x91 0x00 0x00 0x00 0x00 0x00 0x00 0x00 0x00 0x00 0x29 0x0c 0x92 0x40 0x0b 0x0c 0x0d 0x0e 0x00 0x38 0x00 0x10 0x03 0x04 0x29 0x09 0x94 0x00 0x08 0x0b 0x03 0xd2 0x03 0xd3 0x0c 0x29 0x11 0x95 0x00 0x00 0x00 0x00 0x00 0x00 0x00 0x00 0x00 0x00 0x00 0x00 0x00 0x00 0x00 0x00 0x29 0x03 0x99 0x00 0x00 0x29 0x0c 0x9a 0x00 0x00 0x00 0x00 0x00 0x00 0x00 0x00 0x00 0x00 0x00 0x29 0x07 0x9b 0x01 0x38 0x00 0x00 0x00 0x00 0x29 0x03 0x9c 0x00 0x00 0x29 0x09 0x9d 0x10 0x10 0x10 0x10 0x10 0x10 0x00 0x00 0x29 0x03 0x9e 0x00 0x00 0x29 0x0b 0xa0 0x9f 0x1f 0x08 0x1f 0x0a 0x1f 0x00 0x1f 0x14 0x1f 0x29 0x0b 0xa1 0x15 0x1f 0x1f 0x1f 0x1f 0x1f 0x1f 0x1f 0x1f 0x1f 0x29 0x0b 0xa2 0x1f 0x1f 0x1f 0x1f 0x1f 0x1f 0x1f 0x1f 0x1f 0x1f 0x29 0x0b 0xa4 0x1f 0x1f 0x1f 0x1f 0x1f 0x1f 0x1f 0x1f 0x1f 0x1f 0x29 0x0b 0xa5 0x1f 0x1f 0x1f 0x1f 0x1f 0x1f 0x1f 0x1f 0x1f 0x15 0x29 0x0b 0xa6 0x1f 0x14 0x1f 0x01 0x1f 0x0b 0x1f 0x09 0x1f 0x1f 0x29 0x0b 0xa7 0x1f 0x1f 0x0b 0x1f 0x09 0x1f 0x01 0x1f 0x15 0x1f 0x29 0x0b 0xa8 0x14 0x1f 0x1f 0x1f 0x1f 0x1f 0x1f 0x1f 0x1f 0x1f 0x29 0x0b 0xa9 0x1f 0x1f 0x1f 0x1f 0x1f 0x1f 0x1f 0x1f 0x1f 0x1f 0x29 0x0b 0xab 0x1f 0x1f 0x1f 0x1f 0x1f 0x1f 0x1f 0x1f 0x1f 0x1f 0x29 0x0b 0xac 0x1f 0x1f 0x1f 0x1f 0x1f 0x1f 0x1f 0x1f 0x1f 0x14 0x29 0x0b 0xad 0x1f 0x15 0x1f 0x00 0x1f 0x08 0x1f 0x0a 0x1f 0x1f 0x29 0x06 0xf0 0x55 0xaa 0x52 0x08 0x00 0x29 0x04 0xbc 0x00 0x00 0x00 0x29 0x05 0xb8 0x01 0xaf 0x8f 0x8f 0x29 0x06 0xf0 0x55 0xaa 0x52 0x08 0x01 0x29 0x11 0xd1 0x00 0x00 0x00 0x09 0x00 0x1f 0x00 0x30 0x00 0x3f 0x00 0x5d 0x00 0x79 0x00 0xa7 0x29 0x11 0xd2 0x00 0xcf 0x01 0x12 0x01 0x49 0x01 0xa1 0x01 0xeb 0x01 0xed 0x02 0x2f 0x02 0x74 0x29 0x11 0xd3 0x02 0x9f 0x02 0xd5 0x02 0xfb 0x03 0x2c 0x03 0x4b 0x03 0x73 0x03 0x8c 0x03 0xa5 0x29 0x05 0xd4 0x03 0xc5 0x03 0xff 0x29 0x11 0xd5 0x00 0x00 0x00 0x09 0x00 0x1f 0x00 0x30 0x00 0x3f 0x00 0x5d 0x00 0x79 0x00 0xa7 0x29 0x11 0xd6 0x00 0xcf 0x01 0x12 0x01 0x49 0x01 0xa1 0x01 0xeb 0x01 0xed 0x02 0x2f 0x02 0x74 0x29 0x11 0xd7 0x02 0x9f 0x02 0xd5 0x02 0xfb 0x03 0x2c 0x03 0x4b 0x03 0x73 0x03 0x8c 0x03 0xa5 0x29 0x05 0xd8 0x03 0xc5 0x03 0xff 0x29 0x11 0xd9 0x00 0x00 0x00 0x09 0x00 0x1f 0x00 0x30 0x00 0x3f 0x00 0x5d 0x00 0x79 0x00 0xa7 0x29 0x11 0xdd 0x00 0xcf 0x01 0x12 0x01 0x49 0x01 0xa1 0x01 0xeb 0x01 0xed 0x02 0x2f 0x02 0x74 0x29 0x11 0xde 0x02 0x9f 0x02 0xd5 0x02 0xfb 0x03 0x2c 0x03 0x4b 0x03 0x73 0x03 0x8c 0x03 0xa5 0x29 0x05 0xdf 0x03 0xc5 0x03 0xff 0x29 0x11 0xe0 0x00 0x00 0x00 0x09 0x00 0x1f 0x00 0x30 0x00 0x3f 0x00 0x5d 0x00 0x79 0x00 0xa7 0x29 0x11 0xe1 0x00 0xcf 0x01 0x12 0x01 0x49 0x01 0xa1 0x01 0xeb 0x01 0xed 0x02 0x2f 0x02 0x74 0x29 0x11 0xe2 0x02 0x9f 0x02 0xd5 0x02 0xfb 0x03 0x2c 0x03 0x4b 0x03 0x73 0x03 0x8c 0x03 0xa5 0x29 0x05 0xe3 0x03 0xc5 0x03 0xff 0x29 0x11 0xe4 0x00 0x00 0x00 0x09 0x00 0x1f 0x00 0x30 0x00 0x3f 0x00 0x5d 0x00 0x79 0x00 0xa7 0x29 0x11 0xe5 0x00 0xcf 0x01 0x12 0x01 0x49 0x01 0xa1 0x01 0xeb 0x01 0xed 0x02 0x2f 0x02 0x74 0x29 0x11 0xe6 0x02 0x9f 0x02 0xd5 0x02 0xfb 0x03 0x2c 0x03 0x4b 0x03 0x73 0x03 0x8c 0x03 0xa5 0x29 0x05 0xe7 0x03 0xc5 0x03 0xff 0x29 0x11 0xe8 0x00 0x00 0x00 0x09 0x00 0x1f 0x00 0x30 0x00 0x3f 0x00 0x5d 0x00 0x79 0x00 0xa7 0x29 0x11 0xe9 0x00 0xcf 0x01 0x12 0x01 0x49 0x01 0xa1 0x01 0xeb 0x01 0xed 0x02 0x2f 0x02 0x74 0x29 0x11 0xea 0x02 0x9f 0x02 0xd5 0x02 0xfb 0x03 0x2c 0x03 0x4b 0x03 0x73 0x03 0x8c 0x03 0xa5 0x29 0x05 0xeb 0x03 0xc5 0x03 0xff 0x29 0x04 0xb0 0x05 0x05 0x05 0x29 0x04 0xb1 0x05 0x05 0x05 0x29 0x04 0xb3 0x10 0x10 0x10 0x29 0x04 0xb4 0x06 0x06 0x06 0x29 0x04 0xb6 0x44 0x44 0x44 0x29 0x04 0xb7 0x34 0x34 0x34 0x29 0x04 0xb8 0x34 0x34 0x34 0x29 0x04 0xb9 0x24 0x24 0x24 0x29 0x04 0xba 0x24 0x24 0x24 0x29 0x04 0xbc 0x00 0x70 0x00 0x29 0x04 0xbd 0x00 0x70 0x00 0x23 0x02 0xbe 0x50 0x23 0x02 0x35 0x00 0x13 0x01 0x11 0xfd 0x01 0xc8 0x13 0x01 0x29 0xfd 0x01 0xc8 0xff 0x00>;
			init_off = <0x05 0x01 0x28 0xfd 0x01 0x0a 0x05 0x01 0x10 0xfd 0x01 0x96 0xff 0x00>;
		};

		extern_4 {
			index = <0x04>;
			extern_name = "mipi_default";
			status = "okay";
			type = <0x02>;
			cmd_size = <0xff>;
			init_on = <0x23 0x02 0xe0 0x00 0x23 0x02 0xe1 0x93 0x23 0x02 0xe2 0x65 0x23 0x02 0xe3 0xf8 0x23 0x02 0xe0 0x01 0x23 0x02 0x00 0x00 0x23 0x02 0x01 0x90 0x23 0x02 0x03 0x00 0x23 0x02 0x04 0x90 0x23 0x02 0x17 0x00 0x23 0x02 0x18 0xb0 0x23 0x02 0x19 0x01 0x23 0x02 0x1a 0x00 0x23 0x02 0x1b 0xb0 0x23 0x02 0x1c 0x01 0x23 0x02 0x1f 0x3e 0x23 0x02 0x20 0x2f 0x23 0x02 0x21 0x2f 0x23 0x02 0x22 0x0e 0x23 0x02 0x37 0x69 0x23 0x02 0x38 0x05 0x23 0x02 0x39 0x00 0x23 0x02 0x3a 0x01 0x23 0x02 0x3c 0x90 0x23 0x02 0x3d 0xff 0x23 0x02 0x3e 0xff 0x23 0x02 0x3f 0xff 0x23 0x02 0x40 0x02 0x23 0x02 0x41 0x80 0x23 0x02 0x42 0x99 0x23 0x02 0x43 0x06 0x23 0x02 0x44 0x09 0x23 0x02 0x45 0x3c 0x23 0x02 0x4b 0x04 0x23 0x02 0x55 0x0f 0x23 0x02 0x56 0x01 0x23 0x02 0x57 0x89 0x23 0x02 0x58 0x0a 0x23 0x02 0x59 0x0a 0x23 0x02 0x5a 0x27 0x23 0x02 0x5b 0x15 0x23 0x02 0x5d 0x7c 0x23 0x02 0x5e 0x67 0x23 0x02 0x5f 0x58 0x23 0x02 0x60 0x4c 0x23 0x02 0x61 0x48 0x23 0x02 0x62 0x38 0x23 0x02 0x63 0x3c 0x23 0x02 0x64 0x24 0x23 0x02 0x65 0x3b 0x23 0x02 0x66 0x38 0x23 0x02 0x67 0x36 0x23 0x02 0x68 0x53 0x23 0x02 0x69 0x3f 0x23 0x02 0x6a 0x44 0x23 0x02 0x6b 0x35 0x23 0x02 0x6c 0x2e 0x23 0x02 0x6d 0x1f 0x23 0x02 0x6e 0x0c 0x23 0x02 0x6f 0x00 0x23 0x02 0x70 0x7c 0x23 0x02 0x71 0x67 0x23 0x02 0x72 0x58 0x23 0x02 0x73 0x4c 0x23 0x02 0x74 0x48 0x23 0x02 0x75 0x38 0x23 0x02 0x76 0x3c 0x23 0x02 0x77 0x24 0x23 0x02 0x78 0x3b 0x23 0x02 0x79 0x38 0x23 0x02 0x7a 0x36 0x23 0x02 0x7b 0x53 0x23 0x02 0x7c 0x3f 0x23 0x02 0x7d 0x44 0x23 0x02 0x7e 0x35 0x23 0x02 0x7f 0x2e 0x23 0x02 0x80 0x1f 0x23 0x02 0x81 0x0c 0x23 0x02 0x82 0x00 0x23 0x02 0xe0 0x02 0x23 0x02 0x00 0x45 0x23 0x02 0x01 0x45 0x23 0x02 0x02 0x47 0x23 0x02 0x03 0x47 0x23 0x02 0x04 0x41 0x23 0x02 0x05 0x41 0x23 0x02 0x06 0x1f 0x23 0x02 0x07 0x1f 0x23 0x02 0x08 0x1f 0x23 0x02 0x09 0x1f 0x23 0x02 0x0a 0x1f 0x23 0x02 0x0b 0x1f 0x23 0x02 0x0c 0x1f 0x23 0x02 0x0d 0x1d 0x23 0x02 0x0e 0x1d 0x23 0x02 0x0f 0x1d 0x23 0x02 0x10 0x1f 0x23 0x02 0x11 0x1f 0x23 0x02 0x12 0x1f 0x23 0x02 0x13 0x1f 0x23 0x02 0x14 0x1f 0x23 0x02 0x15 0x1f 0x23 0x02 0x16 0x44 0x23 0x02 0x17 0x44 0x23 0x02 0x18 0x46 0x23 0x02 0x19 0x46 0x23 0x02 0x1a 0x40 0x23 0x02 0x1b 0x40 0x23 0x02 0x1c 0x1f 0x23 0x02 0x1d 0x1f 0x23 0x02 0x1e 0x1f 0x23 0x02 0x1f 0x1f 0x23 0x02 0x20 0x1f 0x23 0x02 0x21 0x1f 0x23 0x02 0x22 0x1f 0x23 0x02 0x23 0x1d 0x23 0x02 0x24 0x1d 0x23 0x02 0x25 0x1d 0x23 0x02 0x26 0x1f 0x23 0x02 0x27 0x1f 0x23 0x02 0x28 0x1f 0x23 0x02 0x29 0x1f 0x23 0x02 0x2a 0x1f 0x23 0x02 0x2b 0x1f 0x23 0x02 0x58 0x40 0x23 0x02 0x59 0x00 0x23 0x02 0x5a 0x00 0x23 0x02 0x5b 0x10 0x23 0x02 0x5c 0x06 0x23 0x02 0x5d 0x20 0x23 0x02 0x5e 0x00 0x23 0x02 0x5f 0x00 0x23 0x02 0x61 0x00 0x23 0x02 0x62 0x00 0x23 0x02 0x63 0x7a 0x23 0x02 0x64 0x7a 0x23 0x02 0x65 0x00 0x23 0x02 0x66 0x00 0x23 0x02 0x67 0x32 0x23 0x02 0x68 0x08 0x23 0x02 0x69 0x7a 0x23 0x02 0x6a 0x7a 0x23 0x02 0x6b 0x00 0x23 0x02 0x6c 0x00 0x23 0x02 0x6d 0x04 0x23 0x02 0x6e 0x04 0x23 0x02 0x6f 0x88 0x23 0x02 0x70 0x00 0x23 0x02 0x71 0x00 0x23 0x02 0x72 0x06 0x23 0x02 0x73 0x7b 0x23 0x02 0x74 0x00 0x23 0x02 0x75 0x07 0x23 0x02 0x76 0x00 0x23 0x02 0x77 0x5d 0x23 0x02 0x78 0x17 0x23 0x02 0x79 0x1f 0x23 0x02 0x7a 0x00 0x23 0x02 0x7b 0x00 0x23 0x02 0x7c 0x00 0x23 0x02 0x7d 0x03 0x23 0x02 0x7e 0x7b 0x23 0x02 0xe0 0x03 0x23 0x02 0xaf 0x20 0x23 0x02 0xe0 0x04 0x23 0x02 0x09 0x11 0x23 0x02 0x0e 0x48 0x23 0x02 0x2b 0x2b 0x23 0x02 0x2e 0x44 0x23 0x02 0x41 0xff 0x23 0x02 0xe0 0x00 0x23 0x02 0xe6 0x02 0x23 0x02 0xe7 0x0c 0x05 0x01 0x11 0xfd 0x01 0x78 0x23 0x02 0xe0 0x03 0x23 0x02 0x2b 0x01 0x23 0x02 0x2c 0x00 0x23 0x02 0x30 0x03 0x23 0x02 0x31 0xcc 0x23 0x02 0x32 0x03 0x23 0x02 0x33 0xc9 0x23 0x02 0x34 0x03 0x23 0x02 0x35 0xc0 0x23 0x02 0x36 0x03 0x23 0x02 0x37 0xb3 0x23 0x02 0x38 0x03 0x23 0x02 0x39 0xab 0x23 0x02 0x3a 0x03 0x23 0x02 0x3b 0x9d 0x23 0x02 0x3c 0x03 0x23 0x02 0x3d 0x8f 0x23 0x02 0x3e 0x03 0x23 0x02 0x3f 0x6d 0x23 0x02 0x40 0x03 0x23 0x02 0x41 0x51 0x23 0x02 0x42 0x03 0x23 0x02 0x43 0x17 0x23 0x02 0x44 0x02 0x23 0x02 0x45 0xd8 0x23 0x02 0x46 0x02 0x23 0x02 0x47 0x60 0x23 0x02 0x48 0x01 0x23 0x02 0x49 0xeb 0x23 0x02 0x4a 0x01 0x23 0x02 0x4b 0xe5 0x23 0x02 0x4c 0x01 0x23 0x02 0x4d 0x6c 0x23 0x02 0x4e 0x00 0x23 0x02 0x4f 0xf2 0x23 0x02 0x50 0x00 0x23 0x02 0x51 0xb4 0x23 0x02 0x52 0x00 0x23 0x02 0x53 0x74 0x23 0x02 0x54 0x00 0x23 0x02 0x55 0x54 0x23 0x02 0x56 0x00 0x23 0x02 0x57 0x34 0x23 0x02 0x58 0x00 0x23 0x02 0x59 0x26 0x23 0x02 0x5a 0x00 0x23 0x02 0x5b 0x18 0x23 0x02 0x5c 0x00 0x23 0x02 0x5d 0x11 0x23 0x02 0x5e 0x00 0x23 0x02 0x5f 0x0a 0x23 0x02 0x60 0x00 0x23 0x02 0x61 0x03 0x23 0x02 0x62 0x00 0x23 0x02 0x63 0x00 0x23 0x02 0x64 0x03 0x23 0x02 0x65 0x9e 0x23 0x02 0x66 0x03 0x23 0x02 0x67 0x9b 0x23 0x02 0x68 0x03 0x23 0x02 0x69 0x94 0x23 0x02 0x6a 0x03 0x23 0x02 0x6b 0x8c 0x23 0x02 0x6c 0x03 0x23 0x02 0x6d 0x85 0x23 0x02 0x6e 0x03 0x23 0x02 0x6f 0x76 0x23 0x02 0x70 0x03 0x23 0x02 0x71 0x67 0x23 0x02 0x72 0x03 0x23 0x02 0x73 0x4b 0x23 0x02 0x74 0x03 0x23 0x02 0x75 0x2e 0x23 0x02 0x76 0x02 0x23 0x02 0x77 0xf7 0x23 0x02 0x78 0x02 0x23 0x02 0x79 0xb8 0x23 0x02 0x7a 0x02 0x23 0x02 0x7b 0x46 0x23 0x02 0x7c 0x01 0x23 0x02 0x7d 0xd6 0x23 0x02 0x7e 0x01 0x23 0x02 0x7f 0xd0 0x23 0x02 0x80 0x01 0x23 0x02 0x81 0x5c 0x23 0x02 0x82 0x00 0x23 0x02 0x83 0xe7 0x23 0x02 0x84 0x00 0x23 0x02 0x85 0xaa 0x23 0x02 0x86 0x00 0x23 0x02 0x87 0x74 0x23 0x02 0x88 0x00 0x23 0x02 0x89 0x5a 0x23 0x02 0x8a 0x00 0x23 0x02 0x8b 0x3c 0x23 0x02 0x8c 0x00 0x23 0x02 0x8d 0x2c 0x23 0x02 0x8e 0x00 0x23 0x02 0x8f 0x1c 0x23 0x02 0x90 0x00 0x23 0x02 0x91 0x14 0x23 0x02 0x92 0x00 0x23 0x02 0x93 0x0c 0x23 0x02 0x94 0x00 0x23 0x02 0x95 0x04 0x23 0x02 0x96 0x00 0x23 0x02 0x97 0x00 0x23 0x02 0xe0 0x00 0x05 0x01 0x29 0xfd 0x01 0x05 0xff 0x00>;
			init_off = <0x05 0x01 0x28 0xfd 0x01 0x0a 0x05 0x01 0x10 0xfd 0x01 0x96 0xff 0x00>;
		};

		extern_5 {
			index = <0x05>;
			extern_name = "mipi_default";
			status = "okay";
			type = <0x02>;
			cmd_size = <0xff>;
			init_on = <0x23 0x02 0xe0 0x00 0x23 0x02 0xe1 0x93 0x23 0x02 0xe2 0x65 0x23 0x02 0xe3 0xf8 0x23 0x02 0x80 0x03 0x23 0x02 0xe0 0x01 0x23 0x02 0x0c 0x74 0x23 0x02 0x17 0x00 0x23 0x02 0x18 0xef 0x23 0x02 0x19 0x00 0x23 0x02 0x1a 0x00 0x23 0x02 0x1b 0xef 0x23 0x02 0x1c 0x00 0x23 0x02 0x1f 0x70 0x23 0x02 0x20 0x2d 0x23 0x02 0x21 0x2d 0x23 0x02 0x22 0x7e 0x23 0x02 0x26 0xf3 0x23 0x02 0x37 0x09 0x23 0x02 0x38 0x04 0x23 0x02 0x39 0x00 0x23 0x02 0x3a 0x01 0x23 0x02 0x3c 0x90 0x23 0x02 0x3d 0xff 0x23 0x02 0x3e 0xff 0x23 0x02 0x3f 0xff 0x23 0x02 0x40 0x02 0x23 0x02 0x41 0x80 0x23 0x02 0x42 0x99 0x23 0x02 0x43 0x14 0x23 0x02 0x44 0x19 0x23 0x02 0x45 0x5a 0x23 0x02 0x4b 0x04 0x23 0x02 0x55 0x02 0x23 0x02 0x56 0x01 0x23 0x02 0x57 0x69 0x23 0x02 0x58 0x0a 0x23 0x02 0x59 0x0a 0x23 0x02 0x5a 0x2e 0x23 0x02 0x5b 0x19 0x23 0x02 0x5c 0x15 0x23 0x02 0x5d 0x77 0x23 0x02 0x5e 0x56 0x23 0x02 0x5f 0x45 0x23 0x02 0x60 0x38 0x23 0x02 0x61 0x35 0x23 0x02 0x62 0x27 0x23 0x02 0x63 0x2d 0x23 0x02 0x64 0x18 0x23 0x02 0x65 0x33 0x23 0x02 0x66 0x34 0x23 0x02 0x67 0x35 0x23 0x02 0x68 0x56 0x23 0x02 0x69 0x45 0x23 0x02 0x6a 0x4f 0x23 0x02 0x6b 0x42 0x23 0x02 0x6c 0x40 0x23 0x02 0x6d 0x34 0x23 0x02 0x6e 0x25 0x23 0x02 0x6f 0x02 0x23 0x02 0x70 0x77 0x23 0x02 0x71 0x56 0x23 0x02 0x72 0x45 0x23 0x02 0x73 0x38 0x23 0x02 0x74 0x35 0x23 0x02 0x75 0x27 0x23 0x02 0x76 0x2d 0x23 0x02 0x77 0x18 0x23 0x02 0x78 0x33 0x23 0x02 0x79 0x34 0x23 0x02 0x7a 0x35 0x23 0x02 0x7b 0x56 0x23 0x02 0x7c 0x45 0x23 0x02 0x7d 0x4f 0x23 0x02 0x7e 0x42 0x23 0x02 0x7f 0x40 0x23 0x02 0x80 0x34 0x23 0x02 0x81 0x25 0x23 0x02 0x82 0x02 0x23 0x02 0xe0 0x02 0x23 0x02 0x00 0x53 0x23 0x02 0x01 0x55 0x23 0x02 0x02 0x55 0x23 0x02 0x03 0x51 0x23 0x02 0x04 0x77 0x23 0x02 0x05 0x57 0x23 0x02 0x06 0x1f 0x23 0x02 0x07 0x4f 0x23 0x02 0x08 0x4d 0x23 0x02 0x09 0x1f 0x23 0x02 0x0a 0x4b 0x23 0x02 0x0b 0x49 0x23 0x02 0x0c 0x1f 0x23 0x02 0x0d 0x47 0x23 0x02 0x0e 0x45 0x23 0x02 0x0f 0x41 0x23 0x02 0x10 0x1f 0x23 0x02 0x11 0x1f 0x23 0x02 0x12 0x1f 0x23 0x02 0x13 0x55 0x23 0x02 0x14 0x1f 0x23 0x02 0x15 0x1f 0x23 0x02 0x16 0x52 0x23 0x02 0x17 0x55 0x23 0x02 0x18 0x55 0x23 0x02 0x19 0x50 0x23 0x02 0x1a 0x77 0x23 0x02 0x1b 0x57 0x23 0x02 0x1c 0x1f 0x23 0x02 0x1d 0x4e 0x23 0x02 0x1e 0x4c 0x23 0x02 0x1f 0x1f 0x23 0x02 0x20 0x4a 0x23 0x02 0x21 0x48 0x23 0x02 0x22 0x1f 0x23 0x02 0x23 0x46 0x23 0x02 0x24 0x44 0x23 0x02 0x25 0x40 0x23 0x02 0x26 0x1f 0x23 0x02 0x27 0x1f 0x23 0x02 0x28 0x1f 0x23 0x02 0x29 0x1f 0x23 0x02 0x2a 0x1f 0x23 0x02 0x2b 0x55 0x23 0x02 0x2c 0x12 0x23 0x02 0x2d 0x15 0x23 0x02 0x2e 0x15 0x23 0x02 0x2f 0x00 0x23 0x02 0x30 0x37 0x23 0x02 0x31 0x17 0x23 0x02 0x32 0x1f 0x23 0x02 0x33 0x08 0x23 0x02 0x34 0x0a 0x23 0x02 0x35 0x1f 0x23 0x02 0x36 0x0c 0x23 0x02 0x37 0x0e 0x23 0x02 0x38 0x1f 0x23 0x02 0x39 0x04 0x23 0x02 0x3a 0x06 0x23 0x02 0x3b 0x10 0x23 0x02 0x3c 0x1f 0x23 0x02 0x3d 0x1f 0x23 0x02 0x3e 0x1f 0x23 0x02 0x3f 0x15 0x23 0x02 0x40 0x1f 0x23 0x02 0x41 0x1f 0x23 0x02 0x42 0x13 0x23 0x02 0x43 0x15 0x23 0x02 0x44 0x15 0x23 0x02 0x45 0x01 0x23 0x02 0x46 0x37 0x23 0x02 0x47 0x17 0x23 0x02 0x48 0x1f 0x23 0x02 0x49 0x09 0x23 0x02 0x4a 0x0b 0x23 0x02 0x4b 0x1f 0x23 0x02 0x4c 0x0d 0x23 0x02 0x4d 0x0f 0x23 0x02 0x4e 0x1f 0x23 0x02 0x4f 0x05 0x23 0x02 0x50 0x07 0x23 0x02 0x51 0x11 0x23 0x02 0x52 0x1f 0x23 0x02 0x53 0x1f 0x23 0x02 0x54 0x1f 0x23 0x02 0x55 0x1f 0x23 0x02 0x56 0x1f 0x23 0x02 0x57 0x15 0x23 0x02 0x58 0x40 0x23 0x02 0x59 0x00 0x23 0x02 0x5a 0x00 0x23 0x02 0x5b 0x10 0x23 0x02 0x5c 0x14 0x23 0x02 0x5d 0x40 0x23 0x02 0x5e 0x01 0x23 0x02 0x5f 0x02 0x23 0x02 0x60 0x40 0x23 0x02 0x61 0x03 0x23 0x02 0x62 0x04 0x23 0x02 0x63 0x7a 0x23 0x02 0x64 0x7a 0x23 0x02 0x65 0x74 0x23 0x02 0x66 0x16 0x23 0x02 0x67 0xb4 0x23 0x02 0x68 0x16 0x23 0x02 0x69 0x7a 0x23 0x02 0x6a 0x7a 0x23 0x02 0x6b 0x0c 0x23 0x02 0x6c 0x00 0x23 0x02 0x6d 0x04 0x23 0x02 0x6e 0x04 0x23 0x02 0x6f 0x88 0x23 0x02 0x70 0x00 0x23 0x02 0x71 0x00 0x23 0x02 0x72 0x06 0x23 0x02 0x73 0x7b 0x23 0x02 0x74 0x00 0x23 0x02 0x75 0xbc 0x23 0x02 0x76 0x00 0x23 0x02 0x77 0x04 0x23 0x02 0x78 0x2c 0x23 0x02 0x79 0x00 0x23 0x02 0x7a 0x00 0x23 0x02 0x7b 0x00 0x23 0x02 0x7c 0x00 0x23 0x02 0x7d 0x03 0x23 0x02 0x7e 0x7b 0x23 0x02 0xe0 0x04 0x23 0x02 0x09 0x11 0x23 0x02 0x0e 0x48 0x23 0x02 0x2b 0x2b 0x23 0x02 0x2e 0x44 0x23 0x02 0xe0 0x00 0x23 0x02 0xe6 0x02 0x23 0x02 0xe7 0x0c 0x05 0x01 0x11 0xfd 0x01 0x78 0x05 0x01 0x29 0x05 0x01 0x35 0xfd 0x01 0x14 0xff 0x00>;
			init_off = <0x05 0x01 0x28 0xfd 0x01 0x0a 0x05 0x01 0x10 0xfd 0x01 0x96 0xff 0x00>;
		};

		extern_6 {
			index = <0x06>;
			extern_name = "mipi_ILI9806E";
			status = "okay";
			type = <0x02>;
			cmd_size = <0xff>;
			init_on = <0x39 0x06 0xff 0xff 0x98 0x06 0x04 0x01 0x15 0x02 0x08 0x10 0x15 0x02 0x20 0x00 0x15 0x02 0x21 0x01 0x15 0x02 0x30 0x02 0x15 0x02 0x31 0x02 0x15 0x02 0x60 0x07 0x15 0x02 0x61 0x06 0x15 0x02 0x62 0x06 0x15 0x02 0x63 0x04 0x15 0x02 0x40 0x18 0x15 0x02 0x41 0x33 0x15 0x02 0x42 0x12 0x15 0x02 0x43 0x89 0x15 0x02 0x44 0x86 0x15 0x02 0x46 0x55 0x15 0x02 0x47 0x55 0x15 0x02 0x45 0x14 0x15 0x02 0x50 0x50 0x15 0x02 0x51 0x50 0x15 0x02 0x52 0x00 0x15 0x02 0x53 0x38 0x15 0x02 0xa0 0x00 0x15 0x02 0xa1 0x09 0x15 0x02 0xa2 0x0c 0x15 0x02 0xa3 0x0f 0x15 0x02 0xa4 0x06 0x15 0x02 0xa5 0x09 0x15 0x02 0xa6 0x07 0x15 0x02 0xa7 0x16 0x15 0x02 0xa8 0x06 0x15 0x02 0xa9 0x09 0x15 0x02 0xaa 0x11 0x15 0x02 0xab 0x06 0x15 0x02 0xac 0x0e 0x15 0x02 0xad 0x19 0x15 0x02 0xae 0x0e 0x15 0x02 0xaf 0x00 0x15 0x02 0xc0 0x00 0x15 0x02 0xc1 0x09 0x15 0x02 0xc2 0x0c 0x15 0x02 0xc3 0x0f 0x15 0x02 0xc4 0x06 0x15 0x02 0xc5 0x09 0x15 0x02 0xc6 0x07 0x15 0x02 0xc7 0x16 0x15 0x02 0xc8 0x06 0x15 0x02 0xc9 0x09 0x15 0x02 0xca 0x11 0x15 0x02 0xcb 0x06 0x15 0x02 0xcc 0x0e 0x15 0x02 0xcd 0x19 0x15 0x02 0xce 0x0e 0x15 0x02 0xcf 0x00 0x39 0x06 0xff 0xff 0x98 0x06 0x04 0x06 0x15 0x02 0x00 0xa0 0x15 0x02 0x01 0x05 0x15 0x02 0x02 0x00 0x15 0x02 0x03 0x00 0x15 0x02 0x04 0x01 0x15 0x02 0x05 0x01 0x15 0x02 0x06 0x88 0x15 0x02 0x07 0x04 0x15 0x02 0x08 0x01 0x15 0x02 0x09 0x90 0x15 0x02 0x0a 0x04 0x15 0x02 0x0b 0x01 0x15 0x02 0x0c 0x01 0x15 0x02 0x0d 0x01 0x15 0x02 0x0e 0x00 0x15 0x02 0x0f 0x00 0x15 0x02 0x10 0x55 0x15 0x02 0x11 0x50 0x15 0x02 0x12 0x01 0x15 0x02 0x13 0x85 0x15 0x02 0x14 0x85 0x15 0x02 0x15 0xc0 0x15 0x02 0x16 0x0b 0x15 0x02 0x17 0x00 0x15 0x02 0x18 0x00 0x15 0x02 0x19 0x00 0x15 0x02 0x1a 0x00 0x15 0x02 0x1b 0x00 0x15 0x02 0x1c 0x00 0x15 0x02 0x1d 0x00 0x15 0x02 0x20 0x01 0x15 0x02 0x21 0x23 0x15 0x02 0x22 0x45 0x15 0x02 0x23 0x67 0x15 0x02 0x24 0x01 0x15 0x02 0x25 0x23 0x15 0x02 0x26 0x45 0x15 0x02 0x27 0x67 0x15 0x02 0x30 0x02 0x15 0x02 0x31 0x22 0x15 0x02 0x32 0x11 0x15 0x02 0x33 0xaa 0x15 0x02 0x34 0xbb 0x15 0x02 0x35 0x66 0x15 0x02 0x36 0x00 0x15 0x02 0x37 0x22 0x15 0x02 0x38 0x22 0x15 0x02 0x39 0x22 0x15 0x02 0x3a 0x22 0x15 0x02 0x3b 0x22 0x15 0x02 0x3c 0x22 0x15 0x02 0x3d 0x22 0x15 0x02 0x3e 0x22 0x15 0x02 0x3f 0x22 0x15 0x02 0x40 0x22 0x15 0x02 0x52 0x12 0x15 0x02 0x53 0x12 0x39 0x06 0xff 0xff 0x98 0x06 0x04 0x07 0x15 0x02 0x17 0x32 0x15 0x02 0x02 0x17 0x15 0x02 0x18 0x1d 0x15 0x02 0xe1 0x79 0x39 0x06 0xff 0xff 0x98 0x06 0x04 0x00 0x15 0x02 0x3a 0x70 0x05 0x01 0x11 0xfd 0x01 0x78 0x05 0x01 0x29 0xfd 0x01 0x19 0xff 0xff>;
			init_off = <0x05 0x01 0x28 0xfd 0x01 0x0a 0x05 0x01 0x10 0xfd 0x01 0x1e 0xff 0xff>;
		};

		extern_7 {
			index = <0x07>;
			extern_name = "mipi_ST7701";
			status = "okay";
			type = <0x02>;
			cmd_size = <0xff>;
			init_on = <0x39 0x06 0xff 0x77 0x01 0x00 0x00 0x13 0x39 0x02 0xef 0x08 0x39 0x06 0xff 0x77 0x01 0x00 0x00 0x10 0x39 0x03 0xc0 0x63 0x00 0x39 0x03 0xc1 0x0a 0x02 0x39 0x03 0xc2 0x31 0x07 0x39 0x02 0xcc 0x10 0x39 0x11 0xb0 0x0a 0x10 0x96 0x0e 0x11 0x06 0x06 0x0a 0x08 0x24 0x07 0x53 0x11 0x68 0xad 0xd1 0x39 0x11 0xb1 0x06 0x8d 0xd3 0x09 0x0d 0x04 0x04 0x07 0x07 0x23 0x05 0x15 0x14 0xa7 0xac 0x4f 0x39 0x06 0xff 0x77 0x01 0x00 0x00 0x11 0x39 0x02 0xb0 0x5d 0x39 0x02 0xb1 0x45 0x39 0x02 0xb2 0x82 0x39 0x02 0xb3 0x80 0x39 0x02 0xb5 0x45 0x39 0x02 0xb7 0x85 0x39 0x02 0xb8 0x21 0x39 0x03 0xb9 0x10 0x1f 0x39 0x02 0xbb 0x03 0x39 0x02 0xbc 0x3e 0x39 0x02 0xc1 0x78 0x39 0x02 0xc2 0x78 0x39 0x02 0xd0 0x88 0xfd 0x01 0x08 0x39 0x04 0xe0 0x00 0x00 0x02 0x39 0x0c 0xe1 0x04 0x00 0x00 0x00 0x05 0x00 0x00 0x00 0x00 0x20 0x20 0x39 0x0d 0xe2 0x00 0x00 0x00 0x00 0x00 0x00 0x00 0x00 0x00 0x00 0x00 0x00 0x39 0x05 0xe3 0x00 0x00 0x33 0x00 0x39 0x03 0xe4 0x22 0x00 0x39 0x11 0xe5 0x04 0x34 0x9a 0xa0 0x06 0x34 0x9a 0xa0 0x00 0x00 0x00 0x00 0x00 0x00 0x00 0x00 0x39 0x05 0xe6 0x00 0x00 0x33 0x00 0x39 0x03 0xe7 0x22 0x00 0x39 0x11 0xe8 0x05 0x34 0x9a 0xa0 0x07 0x34 0x9a 0xa0 0x00 0x00 0x00 0x00 0x00 0x00 0x00 0x00 0x39 0x08 0xeb 0x02 0x00 0x40 0x40 0x00 0x00 0x00 0x39 0x03 0xec 0x00 0x00 0x39 0x11 0xed 0xfa 0x45 0x0b 0xff 0xff 0xff 0xff 0xff 0xff 0xff 0xff 0xff 0xff 0xb0 0x54 0xaf 0x39 0x07 0xef 0x08 0x08 0x08 0x45 0x3f 0x54 0x39 0x06 0xff 0x77 0x01 0x00 0x00 0x13 0x39 0x03 0xe8 0x00 0x0e 0x39 0x06 0xff 0x77 0x01 0x00 0x00 0x00 0x39 0x02 0x11 0x00 0xfd 0x01 0x78 0x39 0x06 0xff 0x77 0x01 0x00 0x00 0x13 0x39 0x03 0xe8 0x00 0x0c 0xfd 0x01 0x02 0x39 0x03 0xe8 0x00 0x00 0x39 0x06 0xff 0x77 0x01 0x00 0x00 0x00 0x39 0x02 0x35 0x00 0x39 0x02 0x29 0x00 0xfd 0x01 0x0f 0xff 0xff>;
			init_off = <0x05 0x01 0x28 0xfd 0x01 0x0a 0x05 0x01 0x10 0xfd 0x01 0x1e 0xff 0xff>;
		};

		extern_8 {
			index = <0x08>;
			extern_name = "mipi_ST7701_wily";
			status = "okay";
			type = <0x02>;
			cmd_size = <0xff>;
			init_on = <0x39 0x02 0x11 0x00 0xfd 0x01 0x78 0x39 0x06 0xff 0x77 0x01 0x00 0x00 0x10 0x39 0x03 0xc0 0x63 0x00 0x39 0x03 0xc1 0x11 0x02 0x39 0x03 0xc2 0x01 0x08 0x39 0x02 0xcc 0x18 0x39 0x11 0xb0 0x00 0x88 0x0f 0x0e 0x51 0x07 0x02 0x09 0x08 0x1f 0x06 0x95 0x12 0x24 0xa6 0x88 0x39 0x11 0xb1 0x80 0x8b 0x51 0x0b 0x4f 0x05 0x00 0x07 0x07 0x1e 0x05 0x94 0x14 0x23 0x28 0x48 0x39 0x06 0xff 0x77 0x01 0x00 0x00 0x11 0x39 0x02 0xb0 0x5d 0x39 0x02 0xb1 0x46 0x39 0x02 0xb2 0x07 0x39 0x02 0xb3 0x80 0x39 0x02 0xb5 0x47 0x39 0x02 0xb7 0x85 0x39 0x02 0xb8 0x20 0x39 0x02 0xb9 0x10 0x39 0x02 0xc1 0x78 0x39 0x02 0xc2 0x78 0x39 0x02 0xd0 0x88 0xfd 0x01 0x78 0x39 0x04 0xe0 0x00 0x00 0x02 0x39 0x0c 0xe1 0x08 0x00 0x0a 0x00 0x07 0x00 0x09 0x00 0x00 0x33 0x33 0x39 0x0e 0xe2 0x00 0x00 0x00 0x00 0x00 0x00 0x00 0x00 0x00 0x00 0x00 0x00 0x00 0x39 0x05 0xe3 0x00 0x00 0x33 0x33 0x39 0x03 0xe4 0x44 0x44 0x39 0x11 0xe5 0x0e 0x60 0xa0 0xa0 0x10 0x60 0xa0 0xa0 0x0a 0x60 0xa0 0xa0 0x0c 0x60 0xa0 0xa0 0x39 0x05 0xe6 0x00 0x00 0x33 0x33 0x39 0x03 0xe7 0x44 0x44 0x39 0x11 0xe8 0x0d 0x60 0xa0 0xa0 0x0f 0x60 0xa0 0xa0 0x09 0x60 0xa0 0xa0 0x0b 0x60 0xa0 0xa0 0x39 0x08 0xeb 0x02 0x01 0xe4 0xe4 0x44 0x00 0x40 0x39 0x03 0xec 0x02 0x01 0x39 0x11 0xed 0xab 0x89 0x76 0x54 0x01 0xff 0xff 0xff 0xff 0xff 0xff 0x10 0x45 0x67 0x98 0xba 0x39 0x06 0xff 0x77 0x01 0x00 0x00 0x00 0x39 0x02 0x35 0x00 0x39 0x02 0x29 0x00 0xfd 0x01 0x14 0xff 0x00>;
			init_off = <0x05 0x01 0x28 0xfd 0x01 0x0a 0x05 0x01 0x10 0xfd 0x01 0x1e 0xff 0xff>;
		};

		extern_9 {
			index = <0x09>;
			extern_name = "mipi_ST7701_holitech";
			status = "okay";
			type = <0x02>;
			cmd_size = <0xff>;
			init_on = <0x39 0x06 0xff 0x77 0x01 0x00 0x00 0x13 0x39 0x02 0xef 0x08 0x39 0x06 0xff 0x77 0x01 0x00 0x00 0x10 0x39 0x03 0xc0 0x63 0x00 0x39 0x03 0xc1 0x10 0x02 0x39 0x03 0xc2 0x01 0x08 0x39 0x02 0xcc 0x18 0x39 0x11 0xb0 0x40 0xc9 0x8f 0x0d 0x11 0x07 0x02 0x09 0x09 0x1f 0x04 0x50 0x0f 0xe4 0x29 0xdf 0x39 0x11 0xb1 0x40 0xcb 0xd3 0x11 0x8f 0x04 0x00 0x08 0x07 0x1c 0x06 0x53 0x12 0x63 0xeb 0xdf 0x39 0x06 0xff 0x77 0x01 0x00 0x00 0x11 0x39 0x02 0xb0 0x65 0x39 0x02 0xb1 0x34 0x39 0x02 0xb2 0x87 0x39 0x02 0xb3 0x80 0x39 0x02 0xb5 0x49 0x39 0x02 0xb7 0x85 0x39 0x02 0xb8 0x20 0x39 0x02 0xb9 0x10 0x39 0x02 0xc1 0x78 0x39 0x02 0xc2 0x78 0x39 0x02 0xd0 0x88 0xfd 0x01 0x0a 0x39 0x04 0xe0 0x00 0x19 0x02 0x39 0x0c 0xe1 0x05 0xa0 0x07 0xa0 0x04 0xa0 0x06 0xa0 0x00 0x44 0x44 0x39 0x0d 0xe2 0x00 0x00 0x00 0x00 0x00 0x00 0x00 0x00 0x00 0x00 0x00 0x00 0x39 0x05 0xe3 0x00 0x00 0x33 0x33 0x39 0x03 0xe4 0x44 0x44 0x39 0x11 0xe5 0x0d 0x31 0xc8 0xaf 0x0f 0x33 0xc8 0xaf 0x09 0x2d 0xc8 0xaf 0x0b 0x2f 0xc8 0xaf 0x39 0x05 0xe6 0x00 0x00 0x33 0x33 0x39 0x03 0xe7 0x44 0x44 0x39 0x11 0xe8 0x0c 0x30 0xc8 0xaf 0x0e 0x32 0xc8 0xaf 0x08 0x2c 0xc8 0xaf 0x0a 0x2e 0xc8 0xaf 0x39 0x08 0xeb 0x02 0x00 0xe4 0xe4 0x44 0x00 0x40 0x39 0x03 0xec 0x3c 0x00 0x39 0x11 0xed 0xab 0x89 0x76 0x54 0x01 0xff 0xff 0xff 0xff 0xff 0xff 0x10 0x45 0x67 0x98 0xba 0x39 0x07 0xef 0x08 0x08 0x08 0x45 0x3f 0x54 0x39 0x06 0xff 0x77 0x01 0x00 0x00 0x00 0x39 0x06 0xff 0x77 0x01 0x00 0x00 0x13 0x39 0x03 0xe8 0x00 0x0e 0x39 0x02 0x11 0x00 0xfd 0x01 0x78 0x39 0x03 0xe8 0x00 0x0c 0xfd 0x01 0x0a 0x39 0x03 0xe8 0x00 0x00 0x39 0x06 0xff 0x77 0x01 0x00 0x00 0x00 0x39 0x02 0x29 0x00 0xfd 0x01 0x14 0xff 0x00>;
			init_off = <0x05 0x01 0x28 0xfd 0x01 0x0a 0x05 0x01 0x10 0xfd 0x01 0x1e 0xff 0xff>;
		};
	};

	backlight {
		compatible = "amlogic, backlight-g12a";
		status = "okay";
		key_valid = <0x00>;
		pinctrl-names = "pwm_on", "pwm_off";
		pinctrl-0 = <0x46>;
		pinctrl-1 = <0x47>;
		pinctrl_version = <0x02>;
		bl_pwm_config = <0x48>;
		bl-gpios = <0x15 0x14 0x00 0x15 0x15 0x00>;
		bl_gpio_names = "GPIOH_4", "GPIOH_5";

		backlight_0 {
			index = <0x00>;
			bl_name = "backlight_pwm";
			bl_level_default_uboot_kernel = <0x64 0x64>;
			bl_level_attr = <0xff 0x01 0x80 0x80>;
			bl_ctrl_method = <0x01>;
			bl_power_attr = <0x00 0x01 0x00 0xc8 0xc8>;
			bl_pwm_port = "PWM_F";
			bl_pwm_attr = <0x00 0x7530 0x64 0x00>;
			bl_pwm_power = <0x01 0x01 0x0a 0x0a>;
			bl_pwm_en_sequence_reverse = <0x00>;
		};

		backlight_1 {
			index = <0x01>;
			bl_name = "bl_extern";
			bl_level_default_uboot_kernel = <0x64 0x64>;
			bl_level_attr = <0xff 0x0a 0x80 0x80>;
			bl_ctrl_method = <0x04>;
			bl_power_attr = <0x01 0x01 0x00 0xc8 0xc8>;
			bl_extern_index = <0x00>;
		};
	};

	bl_pwm_conf: bl_pwm_conf {
		phandle = <0x48>;

		pwm_channel_0 {
			pwm_port_index = <0x05>;
			pwms = <0x49 0x01 0x7558 0x00>;
		};
	};

	bl_extern {
		compatible = "amlogic, bl_extern";
		status = "disabled";
		i2c_bus = "i2c_bus_3";

		extern_0 {
			index = <0x00>;
			extern_name = "i2c_lp8556";
			type = <0x00>;
			i2c_address = <0x2c>;
			dim_max_min = <0xff 0x0a>;
		};

		extern_1 {
			index = <0x01>;
			extern_name = "mipi_lt070me05";
			type = <0x02>;
			dim_max_min = <0xff 0x0a>;
		};
	};

	aliases {
		serial0 = "/soc/aobus@ff800000/serial@3000";
		serial1 = "/serial@ffd24000";
		serial2 = "/serial@ffd23000";
		serial3 = "/serial@ffd22000";
		serial4 = "/soc/aobus@ff800000/serial@4000";
		tsensor0 = "/p_tsensor@ff634594";
		tsensor1 = "/d_tsensor@ff800228";
		i2c0 = "/soc/cbus@ffd00000/i2c@1f000";
		i2c1 = "/soc/cbus@ffd00000/i2c@1e000";
		i2c2 = "/soc/cbus@ffd00000/i2c@1d000";
		i2c3 = "/soc/cbus@ffd00000/i2c@1c000";
		i2c4 = "/soc/aobus@ff800000/i2c@5000";
	};

	memory@00000000 {
		device_type = "memory";
		linux,usable-memory = <0x00 0x00 0x00 0x20000000>;
	};

	reserved-memory {
		#address-cells = <0x02>;
		#size-cells = <0x02>;
		ranges;

		ramoops@0x07400000 {
			compatible = "ramoops";
			reg = <0x00 0x7400000 0x00 0x100000>;
			record-size = <0x8000>;
			console-size = <0x8000>;
			ftrace-size = <0x20000>;
		};

		secmon_reserved: linux,secmon {
			compatible = "shared-dma-pool";
			reusable;
			size = <0x00 0x400000>;
			alignment = <0x00 0x400000>;
			alloc-ranges = <0x00 0x5000000 0x00 0x400000>;
			phandle = <0x11>;
		};

		secos_reserved: linux,secos {
			status = "disable";
			compatible = "amlogic, aml_secos_memory";
			reg = <0x00 0x5300000 0x00 0x2000000>;
			no-map;
		};

		logo_reserved: linux,meson-fb {
			compatible = "shared-dma-pool";
			reusable;
			size = <0x00 0x800000>;
			alignment = <0x00 0x400000>;
			alloc-ranges = <0x00 0x1f800000 0x00 0x800000>;
			phandle = <0x2a>;
		};

		ion_cma_reserved: linux,ion-dev {
			compatible = "shared-dma-pool";
			reusable;
			size = <0x00 0x8000000>;
			alignment = <0x00 0x400000>;
			phandle = <0x22>;
		};

		di_cma_reserved: linux,di_cma {
			compatible = "shared-dma-pool";
			reusable;
			size = <0x00 0x2800000>;
			alignment = <0x00 0x400000>;
			phandle = <0x54>;
		};

		ppmgr_reserved: linux,ppmgr {
			compatible = "shared-dma-pool";
			size = <0x00 0x00>;
			phandle = <0x53>;
		};

		codec_mm_cma: linux,codec_mm_cma {
			compatible = "shared-dma-pool";
			reusable;
			size = <0x00 0x13400000>;
			alignment = <0x00 0x400000>;
			linux,contiguous-region;
			phandle = <0x51>;
		};

		codec_mm_reserved: linux,codec_mm_reserved {
			compatible = "amlogic, codec-mm-reserved";
			size = <0x00 0x00>;
			alignment = <0x00 0x100000>;
			phandle = <0x52>;
		};

		vm0_cma_reserved: linux,vm0_cma {
			compatible = "shared-dma-pool";
			reusable;
			size = <0x00 0x2000000>;
			alignment = <0x00 0x400000>;
			phandle = <0x55>;
		};
	};

	gpioleds {
		compatible = "gpio-leds";
		status = "okay";

		sys_led {
			label = "sys_led";
			gpios = <0x4a 0x05 0x00>;
			default-state = "on";
		};
	};

	gpio-keys {
		compatible = "gpio-keys-polled";
		poll-interval = <0x28>;
		status = "okay";
		pinctrl-names = "default";
		pinctrl-0 = <0x4b>;

		preset1 {
			label = "GPIO Key preset1";
			linux,code = <0x02>;
			gpios = <0x15 0x31 0x01>;
		};

		preset2 {
			label = "GPIO Key preset2";
			linux,code = <0x03>;
			gpios = <0x15 0x32 0x01>;
		};

		preset3 {
			label = "GPIO Key preset3";
			linux,code = <0x04>;
			gpios = <0x15 0x33 0x01>;
		};

		preset4 {
			label = "GPIO Key preset4";
			linux,code = <0x05>;
			gpios = <0x15 0x34 0x01>;
		};

		mute {
			label = "GPIO Key mute";
			linux,code = <0x32>;
			gpios = <0x4a 0x03 0x01>;
		};

		back {
			label = "GPIO Key back";
			linux,code = <0x01>;
			gpios = <0x15 0x36 0x01>;
		};

		select {
			label = "GPIO Key select";
			linux,code = <0x1c>;
			gpios = <0x15 0x07 0x01>;
		};
	};

	rotary@0 {
		compatible = "rotary-encoder";
		gpios = <0x15 0x08 0x01>, < 0x15 0x09 0x01>;
		pinctrl-names = "default";
		pinctrl-0 = <0x4c>;
		linux,axis = <0x06>;
		rotary-encoder,encoding = "gray";
		rotary-encoder,relative-axis;
		rotary-encoder,steps-per-period = <0x02>;
		wakeup-source = <0x00>;
	};

	disabled-pins {
		pinctrl-names = "default";
		pinctrl-0 = <0x4d 0x4e 0x4f>;
		status = "okay";
	};

	rt1: thermal-sensor@2 {
		compatible = "generic-adc-thermal";
		#thermal-sensor-cells = <0x00>;
		io-channels = <0x50 0x02>;
		io-channel-names = "sensor-channel";
		temperature-lookup-table = <0x14c08 0x37e 0x13880 0x36e 0x124f8 0x35c 0x11170 0x347 0xfde8 0x32f 0xea60 0x315 0xd6d8 0x2f7 0xc350 0x2d6 0xafc8 0x2b2 0x9c40 0x28a 0x88b8 0x25f 0x7530 0x230 0x61a8 0x200 0x4e20 0x1ce 0x3a98 0x19b 0x2710 0x168 0x1388 0x137 0x00 0x109 0xffffec78 0xdd 0xffffd8f0 0xb6 0xffffc568 0x93 0xffffb1e0 0x75 0xffff9e58 0x5c 0xffff8ad0 0x46 0xffff7748 0x35 0xffff63c0 0x28>;
		phandle = <0x35>;
	};

	rt2: thermal-sensor@3 {
		compatible = "generic-adc-thermal";
		#thermal-sensor-cells = <0x00>;
		io-channels = <0x50 0x03>;
		io-channel-names = "sensor-channel";
		temperature-lookup-table = <0x14c08 0x37e 0x13880 0x36e 0x124f8 0x35c 0x11170 0x347 0xfde8 0x32f 0xea60 0x315 0xd6d8 0x2f7 0xc350 0x2d6 0xafc8 0x2b2 0x9c40 0x28a 0x88b8 0x25f 0x7530 0x230 0x61a8 0x200 0x4e20 0x1ce 0x3a98 0x19b 0x2710 0x168 0x1388 0x137 0x00 0x109 0xffffec78 0xdd 0xffffd8f0 0xb6 0xffffc568 0x93 0xffffb1e0 0x75 0xffff9e58 0x5c 0xffff8ad0 0x46 0xffff7748 0x35 0xffff63c0 0x28>;
		phandle = <0x36>;
	};

	rt3: thermal-sensor@0 {
		compatible = "generic-adc-thermal";
		#thermal-sensor-cells = <0x00>;
		io-channels = <0x50 0x00>;
		io-channel-names = "sensor-channel";
		temperature-lookup-table = <0x14c08 0x37e 0x13880 0x36e 0x124f8 0x35c 0x11170 0x347 0xfde8 0x32f 0xea60 0x315 0xd6d8 0x2f7 0xc350 0x2d6 0xafc8 0x2b2 0x9c40 0x28a 0x88b8 0x25f 0x7530 0x230 0x61a8 0x200 0x4e20 0x1ce 0x3a98 0x19b 0x2710 0x168 0x1388 0x137 0x00 0x109 0xffffec78 0xdd 0xffffd8f0 0xb6 0xffffc568 0x93 0xffffb1e0 0x75 0xffff9e58 0x5c 0xffff8ad0 0x46 0xffff7748 0x35 0xffff63c0 0x28>;
		phandle = <0x37>;
	};

	bluetooth {
		compatible = "brcm,bcm4345c0";
		max-speed = <0x2dc6c0>;
		device-wakeup-gpios = <0x15 0x48 0x01>;
		host-wakeup-gpios = <0x15 0x47 0x01>;
	};

	cvbsout {
		compatible = "amlogic, cvbsout-g12a";
		dev_name = "cvbsout";
		status = "okay";
		clocks = <0x02 0x55 0x02 0x4e 0x02 0x4f 0x02 0x57>;
		clock-names = "venci_top_gate", "venci_0_gate", "venci_1_gate", "vdac_clk_gate";
		clk_path = <0x00>;
		performance = <0x1bf0 0x09 0x1b56 0x333 0x1b12 0x8080 0x1b05 0xfd 0x1c59 0xf850 0xffff 0x00>;
		performance_sarft = <0x1bf0 0x09 0x1b56 0x333 0x1b12 0x00 0x1b05 0x09 0x1c59 0xfc48 0xffff 0x00>;
		performance_revB_telecom = <0x1bf0 0x09 0x1b56 0x546 0x1b12 0x8080 0x1b05 0x09 0x1c59 0xf850 0xffff 0x00>;
	};

	codec_mm {
		compatible = "amlogic, codec, mm";
		memory-region = <0x51 0x52>;
		dev_name = "codec_mm";
		status = "okay";
	};

	ppmgr {
		compatible = "amlogic, ppmgr";
		memory-region = <0x53>;
		dev_name = "ppmgr";
		status = "okay";
	};

	deinterlace {
		compatible = "amlogic, deinterlace";
		status = "okay";
		flag_cma = <0x01>;
		memory-region = <0x54>;
		interrupts = <0x00 0x2e 0x01 0x00 0x28 0x01>;
		interrupt-names = "pre_irq", "post_irq";
		clocks = <0x02 0x9b>, < 0x02 0x9c>;
		clock-names = "vpu_clkb_tmp_composite", "vpu_clkb_composite";
		clock-range = <0x14e 0x29b>;
		buffer-size = <0x3e2c40>;
		post-wr-support = <0x01>;
		nr10bit-support = <0x01>;
		nrds-enable = <0x01>;
		pps-enable = <0x01>;
	};

	ionvideo {
		compatible = "amlogic, ionvideo";
		dev_name = "ionvideo";
		status = "okay";
	};

	vm0 {
		compatible = "amlogic, vm";
		memory-region = <0x55>;
		dev_name = "vm0";
		status = "disabled";
		vm_id = <0x00>;
	};

	unifykey {
		compatible = "amlogic, unifykey";
		status = "ok";
		unifykey-num = <0x12>;
		unifykey-index-0 = <0x56>;
		unifykey-index-1 = <0x57>;
		unifykey-index-2 = <0x58>;
		unifykey-index-3 = <0x59>;
		unifykey-index-4 = <0x5a>;
		unifykey-index-5 = <0x5b>;
		unifykey-index-6 = <0x5c>;
		unifykey-index-7 = <0x5d>;
		unifykey-index-8 = <0x5e>;
		unifykey-index-9 = <0x5f>;
		unifykey-index-10 = <0x60>;
		unifykey-index-11 = <0x61>;
		unifykey-index-12 = <0x62>;
		unifykey-index-13 = <0x63>;
		unifykey-index-14 = <0x64>;
		unifykey-index-15 = <0x65>;
		unifykey-index-16 = <0x66>;
		unifykey-index-17 = <0x67>;

		keysn_0: key_0 {
			key-name = "usid";
			key-device = "normal";
			key-permit = "read", "write", "del";
			phandle = <0x56>;
		};

		keysn_1: key_1 {
			key-name = "mac";
			key-device = "normal";
			key-permit = "read", "write", "del";
			phandle = <0x57>;
		};

		keysn_2: key_2 {
			key-name = "hdcp";
			key-device = "secure";
			key-type = "sha1";
			key-permit = "read", "write", "del";
			phandle = <0x58>;
		};

		keysn_3: key_3 {
			key-name = "secure_boot_set";
			key-device = "efuse";
			key-permit = "write";
			phandle = <0x59>;
		};

		keysn_4: key_4 {
			key-name = "mac_bt";
			key-device = "normal";
			key-permit = "read", "write", "del";
			key-type = "mac";
			phandle = <0x5a>;
		};

		keysn_5: key_5 {
			key-name = "mac_wifi";
			key-device = "normal";
			key-permit = "read", "write", "del";
			key-type = "mac";
			phandle = <0x5b>;
		};

		keysn_6: key_6 {
			key-name = "hdcp2_tx";
			key-device = "normal";
			key-permit = "read", "write", "del";
			phandle = <0x5c>;
		};

		keysn_7: key_7 {
			key-name = "hdcp2_rx";
			key-device = "normal";
			key-permit = "read", "write", "del";
			phandle = <0x5d>;
		};

		keysn_8: key_8 {
			key-name = "widevinekeybox";
			key-device = "secure";
			key-permit = "read", "write", "del";
			phandle = <0x5e>;
		};

		keysn_9: key_9 {
			key-name = "deviceid";
			key-device = "normal";
			key-permit = "read", "write", "del";
			phandle = <0x5f>;
		};

		keysn_10: key_10 {
			key-name = "hdcp22_fw_private";
			key-device = "secure";
			key-permit = "read", "write", "del";
			phandle = <0x60>;
		};

		keysn_11: key_11 {
			key-name = "PlayReadykeybox25";
			key-device = "secure";
			key-permit = "read", "write", "del";
			phandle = <0x61>;
		};

		keysn_12: key_12 {
			key-name = "prpubkeybox";
			key-device = "secure";
			key-permit = "read", "write", "del";
			phandle = <0x62>;
		};

		keysn_13: key_13 {
			key-name = "prprivkeybox";
			key-device = "secure";
			key-permit = "read", "write", "del";
			phandle = <0x63>;
		};

		keysn_14: key_14 {
			key-name = "attestationkeybox";
			key-device = "secure";
			key-permit = "read", "write", "del";
			phandle = <0x64>;
		};

		keysn_15: key_15 {
			key-name = "region_code";
			key-device = "normal";
			key-permit = "read", "write", "del";
			phandle = <0x65>;
		};

		keysn_16: key_16 {
			key-name = "netflix_mgkid";
			key-device = "secure";
			key-permit = "read", "write", "del";
			phandle = <0x66>;
		};

		keysn_17: key_17 {
			key-name = "f_serial";
			key-device = "normal";
			key-permit = "read", "write", "del";
			phandle = <0x67>;
		};
	};

	efusekey: efusekey {
		keynum = <0x05>;
		key0 = <0x68>;
		key1 = <0x69>;
		key2 = <0x6a>;
		key3 = <0x6b>;
		key4 = <0x6c>;
		phandle = <0x39>;

		key_0: key_0 {
			keyname = "mac";
			offset = <0x00>;
			size = <0x06>;
			phandle = <0x68>;
		};

		key_1: key_1 {
			keyname = "mac_bt";
			offset = <0x06>;
			size = <0x06>;
			phandle = <0x69>;
		};

		key_2: key_2 {
			keyname = "mac_wifi";
			offset = <0x0c>;
			size = <0x06>;
			phandle = <0x6a>;
		};

		key_3: key_3 {
			keyname = "usid";
			offset = <0x12>;
			size = <0x10>;
			phandle = <0x6b>;
		};

		key_4: key_4 {
			keyname = "f_serial";
			offset = <0x22>;
			size = <0x0f>;
			phandle = <0x6c>;
		};
	};

	amlvecm {
		compatible = "amlogic, vecm";
		dev_name = "aml_vecm";
		status = "okay";
		gamma_en = <0x00>;
		wb_en = <0x00>;
		cm_en = <0x00>;
		tx_op_color_primary = <0x00>;
	};

	dummy_codec: pdm_codec: dummy {
		#sound-dai-cells = <0x00>;
		compatible = "amlogic, aml_dummy_codec";
		status = "okay";
		phandle = <0x71>;
	};

	amlogic_codec: t9015 {
		#sound-dai-cells = <0x00>;
		compatible = "amlogic, aml_codec_T9015";
		reg = <0x00 0xff632000 0x00 0x2000>;
		is_auge_used = <0x01>;
		tdmout_index = <0x01>;
		status = "okay";
		phandle = <0x6e>;
	};

	audio_effect: eqdrc {
		eqdrc_module = <0x01>;
		lane_mask = <0x01>;
		channel_mask = <0x03>;
		phandle = <0x6f>;
	};

	auge_sound {
		compatible = "amlogic, g12a-sound-card";
		aml-audio-card,name = "AML-AUGESOUND";
		aml-audio-card,loopback = <0x6d>;
		aml-audio-card,aux-devs = <0x6e>;
		avout_mute-gpios = <0x4a 0x02 0x00>;
		aml-audio-card,effect = <0x6f>;

		aml-audio-card,dai-link@3 {
			mclk-fs = <0x40>;
			suffix-name = "alsaPORT-pdm";
			aml-audio-card,widgets = "Microphone", "Left Microphones", "Microphone", "Right Microphones";
			aml-audio-card,routing = "PDM_DIN0", "Left Microphones", "PDM_DIN1", "Right Microphones";

			cpu {
				sound-dai = <0x70>;
			};

			codec {
				sound-dai = <0x71>;
			};
		};
	};

	audiolocker: locker {
		compatible = "amlogic, audiolocker";
		clocks = <0x23 0x22 0x23 0x23 0x23 0x1a 0x23 0x1b 0x02 0x0d 0x02 0x0e>;
		clock-names = "lock_out", "lock_in", "out_src", "in_src", "out_calc", "in_ref";
		interrupts = <0x00 0x01 0x01>;
		interrupt-names = "irq";
		frequency = <0x2ebae40>;
		dividor = <0x31>;
		status = "okay";
	};

	cpu_opp_table0: cpu_opp_table0 {
		compatible = "operating-points-v2";
		opp-shared;
		phandle = <0x0d>;

		opp00 {
			opp-hz = /bits/ 64 <0x5f5e100>;
			opp-microvolt = <0xb2778>;
		};

		opp01 {
			opp-hz = /bits/ 64 <0xee6b280>;
			opp-microvolt = <0xb2778>;
		};

		opp02 {
			opp-hz = /bits/ 64 <0x1dcd6500>;
			opp-microvolt = <0xb2778>;
		};

		opp03 {
			opp-hz = /bits/ 64 <0x27c19cc0>;
			opp-microvolt = <0xb2778>;
		};

		opp04 {
			opp-hz = /bits/ 64 <0x3b9aca00>;
			opp-microvolt = <0xb2778>;
		};

		opp05 {
			opp-hz = /bits/ 64 <0x47868c00>;
			opp-microvolt = <0xb2778>;
		};

		opp06 {
			opp-hz = /bits/ 64 <0x5353c980>;
			opp-microvolt = <0xb9ca8>;
		};

		opp07 {
			opp-hz = /bits/ 64 <0x5a1f4a00>;
			opp-microvolt = <0xc11d8>;
		};

		opp08 {
			opp-hz = /bits/ 64 <0x5fd82200>;
			opp-microvolt = <0xcae18>;
		};

		opp09 {
			opp-hz = /bits/ 64 <0x6590fa00>;
			opp-microvolt = <0xd2348>;
		};

		opp10 {
			opp-hz = /bits/ 64 <0x6b49d200>;
			opp-microvolt = <0xef808>;
		};
	};

	cpu_opp_table1: cpu_opp_table1 {
		compatible = "operating-points-v2";
		opp-shared;
		phandle = <0x0e>;

		opp00 {
			opp-hz = /bits/ 64 <0x5f5e100>;
			opp-microvolt = <0xb2778>;
		};

		opp01 {
			opp-hz = /bits/ 64 <0xee6b280>;
			opp-microvolt = <0xb2778>;
		};

		opp02 {
			opp-hz = /bits/ 64 <0x1dcd6500>;
			opp-microvolt = <0xb2778>;
		};

		opp03 {
			opp-hz = /bits/ 64 <0x27c19cc0>;
			opp-microvolt = <0xb2778>;
		};

		opp04 {
			opp-hz = /bits/ 64 <0x3b9aca00>;
			opp-microvolt = <0xb2778>;
		};

		opp05 {
			opp-hz = /bits/ 64 <0x47868c00>;
			opp-microvolt = <0xb2778>;
		};

		opp06 {
			opp-hz = /bits/ 64 <0x5353c980>;
			opp-microvolt = <0xb9ca8>;
		};

		opp07 {
			opp-hz = /bits/ 64 <0x5a1f4a00>;
			opp-microvolt = <0xc11d8>;
		};

		opp08 {
			opp-hz = /bits/ 64 <0x5fd82200>;
			opp-microvolt = <0xcae18>;
		};

		opp09 {
			opp-hz = /bits/ 64 <0x6590fa00>;
			opp-microvolt = <0xd2348>;
		};

		opp10 {
			opp-hz = /bits/ 64 <0x6b49d200>;
			opp-microvolt = <0xef808>;
		};

		opp11 {
			opp-hz = /bits/ 64 <0x71b9c500>;
			opp-microvolt = <0xf1f18>;
		};
	};

	cpu_opp_table2: cpu_opp_table2 {
		compatible = "operating-points-v2";
		opp-shared;
		phandle = <0x0f>;

		opp00 {
			opp-hz = /bits/ 64 <0x5f5e100>;
			opp-microvolt = <0xb2778>;
		};

		opp01 {
			opp-hz = /bits/ 64 <0xee6b280>;
			opp-microvolt = <0xb2778>;
		};

		opp02 {
			opp-hz = /bits/ 64 <0x1dcd6500>;
			opp-microvolt = <0xb2778>;
		};

		opp03 {
			opp-hz = /bits/ 64 <0x27c19cc0>;
			opp-microvolt = <0xb2778>;
		};

		opp04 {
			opp-hz = /bits/ 64 <0x3b9aca00>;
			opp-microvolt = <0xb2778>;
		};

		opp05 {
			opp-hz = /bits/ 64 <0x47868c00>;
			opp-microvolt = <0xb2778>;
		};

		opp06 {
			opp-hz = /bits/ 64 <0x5353c980>;
			opp-microvolt = <0xb9ca8>;
		};

		opp07 {
			opp-hz = /bits/ 64 <0x5a1f4a00>;
			opp-microvolt = <0xc11d8>;
		};

		opp08 {
			opp-hz = /bits/ 64 <0x5fd82200>;
			opp-microvolt = <0xcae18>;
		};

		opp09 {
			opp-hz = /bits/ 64 <0x6590fa00>;
			opp-microvolt = <0xd2348>;
		};

		opp10 {
			opp-hz = /bits/ 64 <0x6b49d200>;
			opp-microvolt = <0xef808>;
		};

		opp11 {
			opp-hz = /bits/ 64 <0x71b9c500>;
			opp-microvolt = <0xf1f18>;
		};

		opp12 {
			opp-hz = /bits/ 64 <0x7829b800>;
			opp-microvolt = <0xf6d38>;
		};

		opp13 {
			opp-hz = /bits/ 64 <0x7d2b7500>;
			opp-microvolt = <0xf6d38>;
		};
	};

	cpufreq-meson {
		compatible = "amlogic, cpufreq-meson";
		pinctrl-names = "default";
		pinctrl-0 = <0x72>;
		status = "okay";
	};
};
